[part 1 of 2: package /MICROSAR/Dem_swc/ComponentTypes]
AUTOSAR XML (schema 4-2-2)
package /MICROSAR/Dem_swc/ComponentTypes
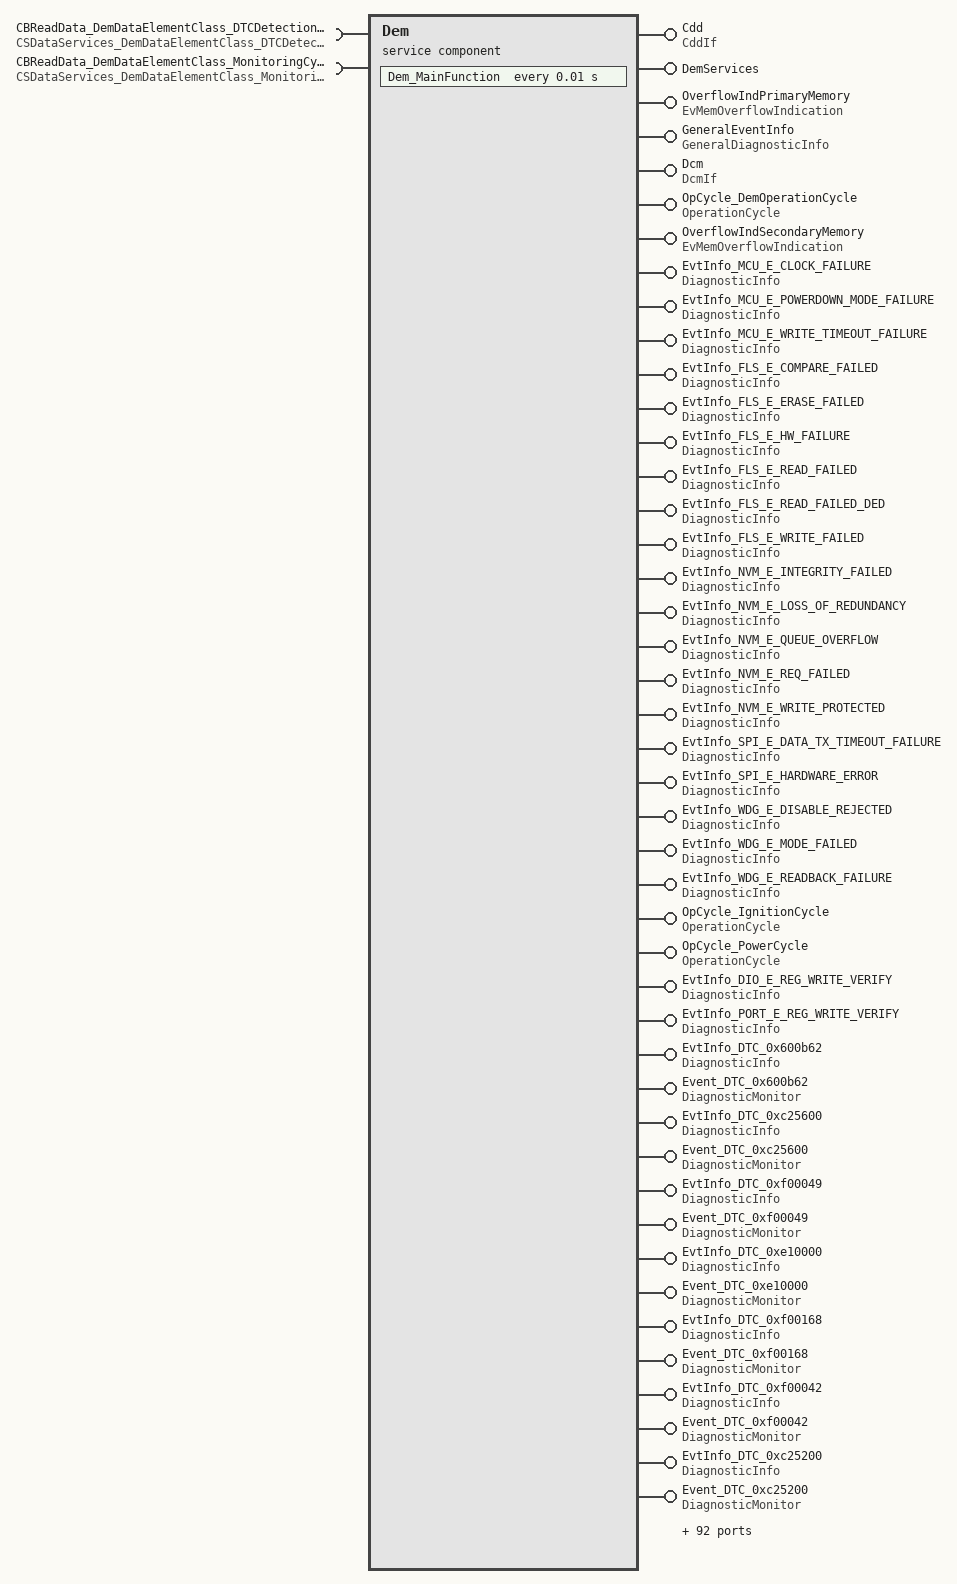
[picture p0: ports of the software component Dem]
  service sw component type Dem: category=SERVICE_COMPONENT
    136 x provide port:
      Cdd: provided-interface=CddIf
      DemServices: provided-interface=DemServices
      OverflowIndPrimaryMemory: provided-interface=EvMemOverflowIndication
      GeneralEventInfo: provided-interface=GeneralDiagnosticInfo
      Dcm: provided-interface=DcmIf
      OpCycle_DemOperationCycle: provided-interface=OperationCycle
      OverflowIndSecondaryMemory: provided-interface=EvMemOverflowIndication
      EvtInfo_MCU_E_CLOCK_FAILURE: provided-interface=DiagnosticInfo
      EvtInfo_MCU_E_POWERDOWN_MODE_FAILURE: provided-interface=DiagnosticInfo
      EvtInfo_MCU_E_WRITE_TIMEOUT_FAILURE: provided-interface=DiagnosticInfo
      EvtInfo_FLS_E_COMPARE_FAILED: provided-interface=DiagnosticInfo
      EvtInfo_FLS_E_ERASE_FAILED: provided-interface=DiagnosticInfo
      EvtInfo_FLS_E_HW_FAILURE: provided-interface=DiagnosticInfo
      EvtInfo_FLS_E_READ_FAILED: provided-interface=DiagnosticInfo
      EvtInfo_FLS_E_READ_FAILED_DED: provided-interface=DiagnosticInfo
      EvtInfo_FLS_E_WRITE_FAILED: provided-interface=DiagnosticInfo
      EvtInfo_NVM_E_INTEGRITY_FAILED: provided-interface=DiagnosticInfo
      EvtInfo_NVM_E_LOSS_OF_REDUNDANCY: provided-interface=DiagnosticInfo
      EvtInfo_NVM_E_QUEUE_OVERFLOW: provided-interface=DiagnosticInfo
      EvtInfo_NVM_E_REQ_FAILED: provided-interface=DiagnosticInfo
      EvtInfo_NVM_E_WRITE_PROTECTED: provided-interface=DiagnosticInfo
      EvtInfo_SPI_E_DATA_TX_TIMEOUT_FAILURE: provided-interface=DiagnosticInfo
      EvtInfo_SPI_E_HARDWARE_ERROR: provided-interface=DiagnosticInfo
      EvtInfo_WDG_E_DISABLE_REJECTED: provided-interface=DiagnosticInfo
      EvtInfo_WDG_E_MODE_FAILED: provided-interface=DiagnosticInfo
      EvtInfo_WDG_E_READBACK_FAILURE: provided-interface=DiagnosticInfo
      OpCycle_IgnitionCycle: provided-interface=OperationCycle
      OpCycle_PowerCycle: provided-interface=OperationCycle
      EvtInfo_DIO_E_REG_WRITE_VERIFY: provided-interface=DiagnosticInfo
      EvtInfo_PORT_E_REG_WRITE_VERIFY: provided-interface=DiagnosticInfo
      EvtInfo_DTC_0x600b62: provided-interface=DiagnosticInfo
      Event_DTC_0x600b62: provided-interface=DiagnosticMonitor
      EvtInfo_DTC_0xc25600: provided-interface=DiagnosticInfo
      Event_DTC_0xc25600: provided-interface=DiagnosticMonitor
      EvtInfo_DTC_0xf00049: provided-interface=DiagnosticInfo
      Event_DTC_0xf00049: provided-interface=DiagnosticMonitor
      EvtInfo_DTC_0xe10000: provided-interface=DiagnosticInfo
      Event_DTC_0xe10000: provided-interface=DiagnosticMonitor
      EvtInfo_DTC_0xf00168: provided-interface=DiagnosticInfo
      Event_DTC_0xf00168: provided-interface=DiagnosticMonitor
      EvtInfo_DTC_0xf00042: provided-interface=DiagnosticInfo
      Event_DTC_0xf00042: provided-interface=DiagnosticMonitor
      EvtInfo_DTC_0xc25200: provided-interface=DiagnosticInfo
      Event_DTC_0xc25200: provided-interface=DiagnosticMonitor
      EvtInfo_DTC_0xe01492: provided-interface=DiagnosticInfo
      Event_DTC_0xe01492: provided-interface=DiagnosticMonitor
      EvtInfo_DTC_0xc41522: provided-interface=DiagnosticInfo
      Event_DTC_0xc41522: provided-interface=DiagnosticMonitor
      EvtInfo_DTC_0xc55700: provided-interface=DiagnosticInfo
      Event_DTC_0xc55700: provided-interface=DiagnosticMonitor
      EvtInfo_DTC_0xc55300: provided-interface=DiagnosticInfo
      Event_DTC_0xc55300: provided-interface=DiagnosticMonitor
      EvtInfo_DTC_0x5b0062: provided-interface=DiagnosticInfo
      Event_DTC_0x5b0062: provided-interface=DiagnosticMonitor
      EvtInfo_DTC_0x511056: provided-interface=DiagnosticInfo
      Event_DTC_0x511056: provided-interface=DiagnosticMonitor
      EvtInfo_DTC_0xc10000: provided-interface=DiagnosticInfo
      Event_DTC_0xc10000: provided-interface=DiagnosticMonitor
      EvtInfo_DTC_0xe01481: provided-interface=DiagnosticInfo
      Event_DTC_0xe01481: provided-interface=DiagnosticMonitor
      EvtInfo_DTC_0xc14600: provided-interface=DiagnosticInfo
      Event_DTC_0xc14600: provided-interface=DiagnosticMonitor
      EvtInfo_DTC_0xe01647: provided-interface=DiagnosticInfo
      Event_DTC_0xe01647: provided-interface=DiagnosticMonitor
      EvtInfo_DTC_0xe01648: provided-interface=DiagnosticInfo
      Event_DTC_0xe01648: provided-interface=DiagnosticMonitor
      EvtInfo_DTC_0xc40100: provided-interface=DiagnosticInfo
      Event_DTC_0xc40100: provided-interface=DiagnosticMonitor
      EvtInfo_DTC_0xc53b00: provided-interface=DiagnosticInfo
      Event_DTC_0xc53b00: provided-interface=DiagnosticMonitor
      EvtInfo_DTC_0xf00061: provided-interface=DiagnosticInfo
      Event_DTC_0xf00061: provided-interface=DiagnosticMonitor
      EvtInfo_DTC_0x600d49: provided-interface=DiagnosticInfo
      Event_DTC_0x600d49: provided-interface=DiagnosticMonitor
      EvtInfo_DTC_0xc55400: provided-interface=DiagnosticInfo
      Event_DTC_0xc55400: provided-interface=DiagnosticMonitor
      EvtInfo_DTC_0xe01478: provided-interface=DiagnosticInfo
      Event_DTC_0xe01478: provided-interface=DiagnosticMonitor
      EvtInfo_DTC_0x502d00: provided-interface=DiagnosticInfo
      Event_DTC_0x502d00: provided-interface=DiagnosticMonitor
      EvtInfo_DTC_0xc12200: provided-interface=DiagnosticInfo
      Event_DTC_0xc12200: provided-interface=DiagnosticMonitor
      EvtInfo_DTC_0xc12600: provided-interface=DiagnosticInfo
      Event_DTC_0xc12600: provided-interface=DiagnosticMonitor
      EvtInfo_DTC_0xf00368: provided-interface=DiagnosticInfo
      Event_DTC_0xf00368: provided-interface=DiagnosticMonitor
      EvtInfo_DTC_0x600d62: provided-interface=DiagnosticInfo
      Event_DTC_0x600d62: provided-interface=DiagnosticMonitor
      EvtInfo_DTC_0xc42300: provided-interface=DiagnosticInfo
      Event_DTC_0xc42300: provided-interface=DiagnosticMonitor
      EvtInfo_DTC_0xc53c00: provided-interface=DiagnosticInfo
      Event_DTC_0xc53c00: provided-interface=DiagnosticMonitor
      EvtInfo_DTC_0xe30055: provided-interface=DiagnosticInfo
      Event_DTC_0xe30055: provided-interface=DiagnosticMonitor
      EvtInfo_DTC_0x600c49: provided-interface=DiagnosticInfo
      Event_DTC_0x600c49: provided-interface=DiagnosticMonitor
      EvtInfo_DTC_0xc23b00: provided-interface=DiagnosticInfo
      Event_DTC_0xc23b00: provided-interface=DiagnosticMonitor
      EvtInfo_DTC_0xc41600: provided-interface=DiagnosticInfo
      Event_DTC_0xc41600: provided-interface=DiagnosticMonitor
      EvtInfo_DTC_0x9d234b: provided-interface=DiagnosticInfo
      Event_DTC_0x9d234b: provided-interface=DiagnosticMonitor
      EvtInfo_DTC_0xc10200: provided-interface=DiagnosticInfo
      Event_DTC_0xc10200: provided-interface=DiagnosticMonitor
      EvtInfo_DTC_0xc12100: provided-interface=DiagnosticInfo
      Event_DTC_0xc12100: provided-interface=DiagnosticMonitor
      EvtInfo_DTC_0xc42800: provided-interface=DiagnosticInfo
      Event_DTC_0xc42800: provided-interface=DiagnosticMonitor
      EvtInfo_DTC_0xc14000: provided-interface=DiagnosticInfo
      Event_DTC_0xc14000: provided-interface=DiagnosticMonitor
      EvtInfo_DTC_0xc45a00: provided-interface=DiagnosticInfo
      Event_DTC_0xc45a00: provided-interface=DiagnosticMonitor
      EvtInfo_DTC_0xc25300: provided-interface=DiagnosticInfo
      Event_DTC_0xc25300: provided-interface=DiagnosticMonitor
      EvtInfo_DTC_0x600c62: provided-interface=DiagnosticInfo
      Event_DTC_0x600c62: provided-interface=DiagnosticMonitor
      EvtInfo_DTC_0xc42200: provided-interface=DiagnosticInfo
      Event_DTC_0xc42200: provided-interface=DiagnosticMonitor
      EvtInfo_DTC_0xc40300: provided-interface=DiagnosticInfo
      Event_DTC_0xc40300: provided-interface=DiagnosticMonitor
      EvtInfo_DTC_0x600b49: provided-interface=DiagnosticInfo
      Event_DTC_0x600b49: provided-interface=DiagnosticMonitor
      EvtInfo_DTC_0xc15900: provided-interface=DiagnosticInfo
      Event_DTC_0xc15900: provided-interface=DiagnosticMonitor
      EvtInfo_DTC_0xc23a00: provided-interface=DiagnosticInfo
      Event_DTC_0xc23a00: provided-interface=DiagnosticMonitor
      EvtInfo_DTC_0xc15500: provided-interface=DiagnosticInfo
      Event_DTC_0xc15500: provided-interface=DiagnosticMonitor
      EvtInfo_DTC_0xc41500: provided-interface=DiagnosticInfo
      Event_DTC_0xc41500: provided-interface=DiagnosticMonitor
      EvtInfo_DTC_0x5b0049: provided-interface=DiagnosticInfo
      Event_DTC_0x5b0049: provided-interface=DiagnosticMonitor
      EvtInfo_DTC_0xf00317: provided-interface=DiagnosticInfo
      Event_DTC_0xf00317: provided-interface=DiagnosticMonitor
      EvtInfo_DTC_0xf00316: provided-interface=DiagnosticInfo
      Event_DTC_0xf00316: provided-interface=DiagnosticMonitor
    require port CBReadData_DemDataElementClass_DTCDetectionCounter: required-interface=CSDataServices_DemDataElementClass_DTCDetectionCounter
    require port CBReadData_DemDataElementClass_MonitoringCycleCounter2: required-interface=CSDataServices_DemDataElementClass_MonitoringCycleCounter2
    behavior DemInternalBehavior: handle-termination-and-restart=NO-SUPPORT, included-data-type-set=data-type=[Dem_EventIdType, Dem_RatioIdType, Dem_EventStatusType, Dem_EventStatusExtendedType, Dem_UdsStatusByteType, Dem_DTCFormatType, Dem_InitMonitorReasonType, Dem_OperationCycleStateType, Dem_DTCStatusMaskType, Dem_IndicatorStatusType, Dem_MaxDataValueType, Dem_DTCKindType, Dem_DTCGroupType, Dem_IumprDenomCondIdType, Dem_IumprDenomCondStatusType, Dem_DebounceResetStatusType, Dem_DebouncingStateType]
      timing event Timer_Dem_MainFunction: start-on-event=Dem_MainFunction, period=0.01
      1220 x operation invoked event:
        OpEventClearDTC_ClearDTC_Cdd: start-on-event=ClearDTC, operation=Cdd.ClearDTC
        OpEventPostRunRequested_GetPostRunRequested_DemServices: start-on-event=PostRunRequested, operation=DemServices.GetPostRunRequested
        OpEventGetDTCStatusAvailabilityMask_GetDTCStatusAvailabilityMask_DemServices: start-on-event=GetDTCStatusAvailabilityMask, operation=DemServices.GetDTCStatusAvailabilityMask
        OpEventGetEventMemoryOverflow_GetEventMemoryOverflow_OverflowIndPrimaryMemory: start-on-event=GetEventMemoryOverflow, operation=OverflowIndPrimaryMemory.GetEventMemoryOverflow
        OpEventGetNumberOfEventMemoryEntries_GetNumberOfEventMemoryEntries_OverflowIndPrimaryMemory: start-on-event=GetNumberOfEventMemoryEntries, operation=OverflowIndPrimaryMemory.GetNumberOfEventMemoryEntries
        OpEventGetEventStatus_GetEventStatus_GeneralEventInfo: start-on-event=GetEventStatus, operation=GeneralEventInfo.GetEventStatus
        OpEventGetEventFailed_GetEventFailed_GeneralEventInfo: start-on-event=GetEventFailed, operation=GeneralEventInfo.GetEventFailed
        OpEventGetEventTested_GetEventTested_GeneralEventInfo: start-on-event=GetEventTested, operation=GeneralEventInfo.GetEventTested
        OpEventGetDTCOfEvent_GetDTCOfEvent_GeneralEventInfo: start-on-event=GetDTCOfEvent, operation=GeneralEventInfo.GetDTCOfEvent
        OpEventGetFaultDetectionCounter_GetFaultDetectionCounter_GeneralEventInfo: start-on-event=GetFaultDetectionCounter, operation=GeneralEventInfo.GetFaultDetectionCounter
        OpEventGetEventFreezeFrameData_GetEventFreezeFrameData_GeneralEventInfo: start-on-event=GetEventFreezeFrameData, operation=GeneralEventInfo.GetEventFreezeFrameData
        OpEventGetEventExtendedDataRecord_GetEventExtendedDataRecord_GeneralEventInfo: start-on-event=GetEventExtendedDataRecord, operation=GeneralEventInfo.GetEventExtendedDataRecord
        OpEventGetEventEnableCondition_GetEventEnableCondition_GeneralEventInfo: start-on-event=GetEventEnableCondition, operation=GeneralEventInfo.GetEventEnableCondition
        OpEventGetDebouncingOfEvent_GetDebouncingOfEvent_GeneralEventInfo: start-on-event=GetDebouncingOfEvent, operation=GeneralEventInfo.GetDebouncingOfEvent
        OpEventDcmClearDTC_DcmClearDTC_Dcm: start-on-event=DcmClearDTC, operation=Dcm.DcmClearDTC
        OpEventDcmGetNextFilteredDTCAndFDC_DcmGetNextFilteredDTCAndFDC_Dcm: start-on-event=DcmGetNextFilteredDTCAndFDC, operation=Dcm.DcmGetNextFilteredDTCAndFDC
        OpEventDcmEnableDTCSetting_DcmEnableDTCSetting_Dcm: start-on-event=DcmEnableDTCSetting, operation=Dcm.DcmEnableDTCSetting
        OpEventDcmGetFreezeFrameDataByDTC_DcmGetFreezeFrameDataByDTC_Dcm: start-on-event=DcmGetFreezeFrameDataByDTC, operation=Dcm.DcmGetFreezeFrameDataByDTC
        OpEventDcmGetExtendedDataRecordByDTC_DcmGetExtendedDataRecordByDTC_Dcm: start-on-event=DcmGetExtendedDataRecordByDTC, operation=Dcm.DcmGetExtendedDataRecordByDTC
        OpEventSetOperationCycleState_SetOperationCycleState_OpCycle_DemOperationCycle: start-on-event=SetOperationCycleState, operation=OpCycle_DemOperationCycle.SetOperationCycleState
        OpEventGetEventMemoryOverflow_GetEventMemoryOverflow_OverflowIndSecondaryMemory: start-on-event=GetEventMemoryOverflow, operation=OverflowIndSecondaryMemory.GetEventMemoryOverflow
        OpEventGetNumberOfEventMemoryEntries_GetNumberOfEventMemoryEntries_OverflowIndSecondaryMemory: start-on-event=GetNumberOfEventMemoryEntries, operation=OverflowIndSecondaryMemory.GetNumberOfEventMemoryEntries
        OpEventGetEventStatus_GetEventStatus_EvtInfo_MCU_E_CLOCK_FAILURE: start-on-event=GetEventStatus, operation=EvtInfo_MCU_E_CLOCK_FAILURE.GetEventStatus
        OpEventGetEventStatus_GetEventStatus_EvtInfo_MCU_E_POWERDOWN_MODE_FAILURE: start-on-event=GetEventStatus, operation=EvtInfo_MCU_E_POWERDOWN_MODE_FAILURE.GetEventStatus
        OpEventGetEventStatus_GetEventStatus_EvtInfo_MCU_E_WRITE_TIMEOUT_FAILURE: start-on-event=GetEventStatus, operation=EvtInfo_MCU_E_WRITE_TIMEOUT_FAILURE.GetEventStatus
        OpEventGetEventStatus_GetEventStatus_EvtInfo_FLS_E_COMPARE_FAILED: start-on-event=GetEventStatus, operation=EvtInfo_FLS_E_COMPARE_FAILED.GetEventStatus
        OpEventGetEventStatus_GetEventStatus_EvtInfo_FLS_E_ERASE_FAILED: start-on-event=GetEventStatus, operation=EvtInfo_FLS_E_ERASE_FAILED.GetEventStatus
        OpEventGetEventStatus_GetEventStatus_EvtInfo_FLS_E_HW_FAILURE: start-on-event=GetEventStatus, operation=EvtInfo_FLS_E_HW_FAILURE.GetEventStatus
        OpEventGetEventStatus_GetEventStatus_EvtInfo_FLS_E_READ_FAILED: start-on-event=GetEventStatus, operation=EvtInfo_FLS_E_READ_FAILED.GetEventStatus
        OpEventGetEventStatus_GetEventStatus_EvtInfo_FLS_E_READ_FAILED_DED: start-on-event=GetEventStatus, operation=EvtInfo_FLS_E_READ_FAILED_DED.GetEventStatus
        OpEventGetEventStatus_GetEventStatus_EvtInfo_FLS_E_WRITE_FAILED: start-on-event=GetEventStatus, operation=EvtInfo_FLS_E_WRITE_FAILED.GetEventStatus
        OpEventGetEventStatus_GetEventStatus_EvtInfo_NVM_E_INTEGRITY_FAILED: start-on-event=GetEventStatus, operation=EvtInfo_NVM_E_INTEGRITY_FAILED.GetEventStatus
        OpEventGetEventStatus_GetEventStatus_EvtInfo_NVM_E_LOSS_OF_REDUNDANCY: start-on-event=GetEventStatus, operation=EvtInfo_NVM_E_LOSS_OF_REDUNDANCY.GetEventStatus
        OpEventGetEventStatus_GetEventStatus_EvtInfo_NVM_E_QUEUE_OVERFLOW: start-on-event=GetEventStatus, operation=EvtInfo_NVM_E_QUEUE_OVERFLOW.GetEventStatus
        OpEventGetEventStatus_GetEventStatus_EvtInfo_NVM_E_REQ_FAILED: start-on-event=GetEventStatus, operation=EvtInfo_NVM_E_REQ_FAILED.GetEventStatus
        OpEventGetEventStatus_GetEventStatus_EvtInfo_NVM_E_WRITE_PROTECTED: start-on-event=GetEventStatus, operation=EvtInfo_NVM_E_WRITE_PROTECTED.GetEventStatus
        OpEventGetEventStatus_GetEventStatus_EvtInfo_SPI_E_DATA_TX_TIMEOUT_FAILURE: start-on-event=GetEventStatus, operation=EvtInfo_SPI_E_DATA_TX_TIMEOUT_FAILURE.GetEventStatus
        OpEventGetEventStatus_GetEventStatus_EvtInfo_SPI_E_HARDWARE_ERROR: start-on-event=GetEventStatus, operation=EvtInfo_SPI_E_HARDWARE_ERROR.GetEventStatus
        OpEventGetEventStatus_GetEventStatus_EvtInfo_WDG_E_DISABLE_REJECTED: start-on-event=GetEventStatus, operation=EvtInfo_WDG_E_DISABLE_REJECTED.GetEventStatus
        OpEventGetEventStatus_GetEventStatus_EvtInfo_WDG_E_MODE_FAILED: start-on-event=GetEventStatus, operation=EvtInfo_WDG_E_MODE_FAILED.GetEventStatus
        OpEventGetEventStatus_GetEventStatus_EvtInfo_WDG_E_READBACK_FAILURE: start-on-event=GetEventStatus, operation=EvtInfo_WDG_E_READBACK_FAILURE.GetEventStatus
        OpEventGetEventFailed_GetEventFailed_EvtInfo_MCU_E_CLOCK_FAILURE: start-on-event=GetEventFailed, operation=EvtInfo_MCU_E_CLOCK_FAILURE.GetEventFailed
        OpEventGetEventFailed_GetEventFailed_EvtInfo_MCU_E_POWERDOWN_MODE_FAILURE: start-on-event=GetEventFailed, operation=EvtInfo_MCU_E_POWERDOWN_MODE_FAILURE.GetEventFailed
        OpEventGetEventFailed_GetEventFailed_EvtInfo_MCU_E_WRITE_TIMEOUT_FAILURE: start-on-event=GetEventFailed, operation=EvtInfo_MCU_E_WRITE_TIMEOUT_FAILURE.GetEventFailed
        OpEventGetEventFailed_GetEventFailed_EvtInfo_FLS_E_COMPARE_FAILED: start-on-event=GetEventFailed, operation=EvtInfo_FLS_E_COMPARE_FAILED.GetEventFailed
        OpEventGetEventFailed_GetEventFailed_EvtInfo_FLS_E_ERASE_FAILED: start-on-event=GetEventFailed, operation=EvtInfo_FLS_E_ERASE_FAILED.GetEventFailed
        OpEventGetEventFailed_GetEventFailed_EvtInfo_FLS_E_HW_FAILURE: start-on-event=GetEventFailed, operation=EvtInfo_FLS_E_HW_FAILURE.GetEventFailed
        OpEventGetEventFailed_GetEventFailed_EvtInfo_FLS_E_READ_FAILED: start-on-event=GetEventFailed, operation=EvtInfo_FLS_E_READ_FAILED.GetEventFailed
        OpEventGetEventFailed_GetEventFailed_EvtInfo_FLS_E_READ_FAILED_DED: start-on-event=GetEventFailed, operation=EvtInfo_FLS_E_READ_FAILED_DED.GetEventFailed
        OpEventGetEventFailed_GetEventFailed_EvtInfo_FLS_E_WRITE_FAILED: start-on-event=GetEventFailed, operation=EvtInfo_FLS_E_WRITE_FAILED.GetEventFailed
        OpEventGetEventFailed_GetEventFailed_EvtInfo_NVM_E_INTEGRITY_FAILED: start-on-event=GetEventFailed, operation=EvtInfo_NVM_E_INTEGRITY_FAILED.GetEventFailed
        OpEventGetEventFailed_GetEventFailed_EvtInfo_NVM_E_LOSS_OF_REDUNDANCY: start-on-event=GetEventFailed, operation=EvtInfo_NVM_E_LOSS_OF_REDUNDANCY.GetEventFailed
        OpEventGetEventFailed_GetEventFailed_EvtInfo_NVM_E_QUEUE_OVERFLOW: start-on-event=GetEventFailed, operation=EvtInfo_NVM_E_QUEUE_OVERFLOW.GetEventFailed
        OpEventGetEventFailed_GetEventFailed_EvtInfo_NVM_E_REQ_FAILED: start-on-event=GetEventFailed, operation=EvtInfo_NVM_E_REQ_FAILED.GetEventFailed
        OpEventGetEventFailed_GetEventFailed_EvtInfo_NVM_E_WRITE_PROTECTED: start-on-event=GetEventFailed, operation=EvtInfo_NVM_E_WRITE_PROTECTED.GetEventFailed
        OpEventGetEventFailed_GetEventFailed_EvtInfo_SPI_E_DATA_TX_TIMEOUT_FAILURE: start-on-event=GetEventFailed, operation=EvtInfo_SPI_E_DATA_TX_TIMEOUT_FAILURE.GetEventFailed
        OpEventGetEventFailed_GetEventFailed_EvtInfo_SPI_E_HARDWARE_ERROR: start-on-event=GetEventFailed, operation=EvtInfo_SPI_E_HARDWARE_ERROR.GetEventFailed
        OpEventGetEventFailed_GetEventFailed_EvtInfo_WDG_E_DISABLE_REJECTED: start-on-event=GetEventFailed, operation=EvtInfo_WDG_E_DISABLE_REJECTED.GetEventFailed
        OpEventGetEventFailed_GetEventFailed_EvtInfo_WDG_E_MODE_FAILED: start-on-event=GetEventFailed, operation=EvtInfo_WDG_E_MODE_FAILED.GetEventFailed
        OpEventGetEventFailed_GetEventFailed_EvtInfo_WDG_E_READBACK_FAILURE: start-on-event=GetEventFailed, operation=EvtInfo_WDG_E_READBACK_FAILURE.GetEventFailed
        OpEventGetEventTested_GetEventTested_EvtInfo_MCU_E_CLOCK_FAILURE: start-on-event=GetEventTested, operation=EvtInfo_MCU_E_CLOCK_FAILURE.GetEventTested
        OpEventGetEventTested_GetEventTested_EvtInfo_MCU_E_POWERDOWN_MODE_FAILURE: start-on-event=GetEventTested, operation=EvtInfo_MCU_E_POWERDOWN_MODE_FAILURE.GetEventTested
        OpEventGetEventTested_GetEventTested_EvtInfo_MCU_E_WRITE_TIMEOUT_FAILURE: start-on-event=GetEventTested, operation=EvtInfo_MCU_E_WRITE_TIMEOUT_FAILURE.GetEventTested
        OpEventGetEventTested_GetEventTested_EvtInfo_FLS_E_COMPARE_FAILED: start-on-event=GetEventTested, operation=EvtInfo_FLS_E_COMPARE_FAILED.GetEventTested
        OpEventGetEventTested_GetEventTested_EvtInfo_FLS_E_ERASE_FAILED: start-on-event=GetEventTested, operation=EvtInfo_FLS_E_ERASE_FAILED.GetEventTested
        OpEventGetEventTested_GetEventTested_EvtInfo_FLS_E_HW_FAILURE: start-on-event=GetEventTested, operation=EvtInfo_FLS_E_HW_FAILURE.GetEventTested
        OpEventGetEventTested_GetEventTested_EvtInfo_FLS_E_READ_FAILED: start-on-event=GetEventTested, operation=EvtInfo_FLS_E_READ_FAILED.GetEventTested
        OpEventGetEventTested_GetEventTested_EvtInfo_FLS_E_READ_FAILED_DED: start-on-event=GetEventTested, operation=EvtInfo_FLS_E_READ_FAILED_DED.GetEventTested
        OpEventGetEventTested_GetEventTested_EvtInfo_FLS_E_WRITE_FAILED: start-on-event=GetEventTested, operation=EvtInfo_FLS_E_WRITE_FAILED.GetEventTested
        OpEventGetEventTested_GetEventTested_EvtInfo_NVM_E_INTEGRITY_FAILED: start-on-event=GetEventTested, operation=EvtInfo_NVM_E_INTEGRITY_FAILED.GetEventTested
        OpEventGetEventTested_GetEventTested_EvtInfo_NVM_E_LOSS_OF_REDUNDANCY: start-on-event=GetEventTested, operation=EvtInfo_NVM_E_LOSS_OF_REDUNDANCY.GetEventTested
        OpEventGetEventTested_GetEventTested_EvtInfo_NVM_E_QUEUE_OVERFLOW: start-on-event=GetEventTested, operation=EvtInfo_NVM_E_QUEUE_OVERFLOW.GetEventTested
        OpEventGetEventTested_GetEventTested_EvtInfo_NVM_E_REQ_FAILED: start-on-event=GetEventTested, operation=EvtInfo_NVM_E_REQ_FAILED.GetEventTested
        OpEventGetEventTested_GetEventTested_EvtInfo_NVM_E_WRITE_PROTECTED: start-on-event=GetEventTested, operation=EvtInfo_NVM_E_WRITE_PROTECTED.GetEventTested
        OpEventGetEventTested_GetEventTested_EvtInfo_SPI_E_DATA_TX_TIMEOUT_FAILURE: start-on-event=GetEventTested, operation=EvtInfo_SPI_E_DATA_TX_TIMEOUT_FAILURE.GetEventTested
        OpEventGetEventTested_GetEventTested_EvtInfo_SPI_E_HARDWARE_ERROR: start-on-event=GetEventTested, operation=EvtInfo_SPI_E_HARDWARE_ERROR.GetEventTested
        OpEventGetEventTested_GetEventTested_EvtInfo_WDG_E_DISABLE_REJECTED: start-on-event=GetEventTested, operation=EvtInfo_WDG_E_DISABLE_REJECTED.GetEventTested
        OpEventGetEventTested_GetEventTested_EvtInfo_WDG_E_MODE_FAILED: start-on-event=GetEventTested, operation=EvtInfo_WDG_E_MODE_FAILED.GetEventTested
        OpEventGetEventTested_GetEventTested_EvtInfo_WDG_E_READBACK_FAILURE: start-on-event=GetEventTested, operation=EvtInfo_WDG_E_READBACK_FAILURE.GetEventTested
        OpEventGetDTCOfEvent_GetDTCOfEvent_EvtInfo_MCU_E_CLOCK_FAILURE: start-on-event=GetDTCOfEvent, operation=EvtInfo_MCU_E_CLOCK_FAILURE.GetDTCOfEvent
        OpEventGetDTCOfEvent_GetDTCOfEvent_EvtInfo_MCU_E_POWERDOWN_MODE_FAILURE: start-on-event=GetDTCOfEvent, operation=EvtInfo_MCU_E_POWERDOWN_MODE_FAILURE.GetDTCOfEvent
        OpEventGetDTCOfEvent_GetDTCOfEvent_EvtInfo_MCU_E_WRITE_TIMEOUT_FAILURE: start-on-event=GetDTCOfEvent, operation=EvtInfo_MCU_E_WRITE_TIMEOUT_FAILURE.GetDTCOfEvent
        OpEventGetDTCOfEvent_GetDTCOfEvent_EvtInfo_FLS_E_COMPARE_FAILED: start-on-event=GetDTCOfEvent, operation=EvtInfo_FLS_E_COMPARE_FAILED.GetDTCOfEvent
        OpEventGetDTCOfEvent_GetDTCOfEvent_EvtInfo_FLS_E_ERASE_FAILED: start-on-event=GetDTCOfEvent, operation=EvtInfo_FLS_E_ERASE_FAILED.GetDTCOfEvent
        OpEventGetDTCOfEvent_GetDTCOfEvent_EvtInfo_FLS_E_HW_FAILURE: start-on-event=GetDTCOfEvent, operation=EvtInfo_FLS_E_HW_FAILURE.GetDTCOfEvent
        OpEventGetDTCOfEvent_GetDTCOfEvent_EvtInfo_FLS_E_READ_FAILED: start-on-event=GetDTCOfEvent, operation=EvtInfo_FLS_E_READ_FAILED.GetDTCOfEvent
        OpEventGetDTCOfEvent_GetDTCOfEvent_EvtInfo_FLS_E_READ_FAILED_DED: start-on-event=GetDTCOfEvent, operation=EvtInfo_FLS_E_READ_FAILED_DED.GetDTCOfEvent
        OpEventGetDTCOfEvent_GetDTCOfEvent_EvtInfo_FLS_E_WRITE_FAILED: start-on-event=GetDTCOfEvent, operation=EvtInfo_FLS_E_WRITE_FAILED.GetDTCOfEvent
        OpEventGetDTCOfEvent_GetDTCOfEvent_EvtInfo_NVM_E_INTEGRITY_FAILED: start-on-event=GetDTCOfEvent, operation=EvtInfo_NVM_E_INTEGRITY_FAILED.GetDTCOfEvent
        OpEventGetDTCOfEvent_GetDTCOfEvent_EvtInfo_NVM_E_LOSS_OF_REDUNDANCY: start-on-event=GetDTCOfEvent, operation=EvtInfo_NVM_E_LOSS_OF_REDUNDANCY.GetDTCOfEvent
        OpEventGetDTCOfEvent_GetDTCOfEvent_EvtInfo_NVM_E_QUEUE_OVERFLOW: start-on-event=GetDTCOfEvent, operation=EvtInfo_NVM_E_QUEUE_OVERFLOW.GetDTCOfEvent
        OpEventGetDTCOfEvent_GetDTCOfEvent_EvtInfo_NVM_E_REQ_FAILED: start-on-event=GetDTCOfEvent, operation=EvtInfo_NVM_E_REQ_FAILED.GetDTCOfEvent
        OpEventGetDTCOfEvent_GetDTCOfEvent_EvtInfo_NVM_E_WRITE_PROTECTED: start-on-event=GetDTCOfEvent, operation=EvtInfo_NVM_E_WRITE_PROTECTED.GetDTCOfEvent
        OpEventGetDTCOfEvent_GetDTCOfEvent_EvtInfo_SPI_E_DATA_TX_TIMEOUT_FAILURE: start-on-event=GetDTCOfEvent, operation=EvtInfo_SPI_E_DATA_TX_TIMEOUT_FAILURE.GetDTCOfEvent
        OpEventGetDTCOfEvent_GetDTCOfEvent_EvtInfo_SPI_E_HARDWARE_ERROR: start-on-event=GetDTCOfEvent, operation=EvtInfo_SPI_E_HARDWARE_ERROR.GetDTCOfEvent
        OpEventGetDTCOfEvent_GetDTCOfEvent_EvtInfo_WDG_E_DISABLE_REJECTED: start-on-event=GetDTCOfEvent, operation=EvtInfo_WDG_E_DISABLE_REJECTED.GetDTCOfEvent
        OpEventGetDTCOfEvent_GetDTCOfEvent_EvtInfo_WDG_E_MODE_FAILED: start-on-event=GetDTCOfEvent, operation=EvtInfo_WDG_E_MODE_FAILED.GetDTCOfEvent
        OpEventGetDTCOfEvent_GetDTCOfEvent_EvtInfo_WDG_E_READBACK_FAILURE: start-on-event=GetDTCOfEvent, operation=EvtInfo_WDG_E_READBACK_FAILURE.GetDTCOfEvent
        OpEventGetFaultDetectionCounter_GetFaultDetectionCounter_EvtInfo_MCU_E_CLOCK_FAILURE: start-on-event=GetFaultDetectionCounter, operation=EvtInfo_MCU_E_CLOCK_FAILURE.GetFaultDetectionCounter
        OpEventGetFaultDetectionCounter_GetFaultDetectionCounter_EvtInfo_MCU_E_POWERDOWN_MODE_FAILURE: start-on-event=GetFaultDetectionCounter, operation=EvtInfo_MCU_E_POWERDOWN_MODE_FAILURE.GetFaultDetectionCounter
        OpEventGetFaultDetectionCounter_GetFaultDetectionCounter_EvtInfo_MCU_E_WRITE_TIMEOUT_FAILURE: start-on-event=GetFaultDetectionCounter, operation=EvtInfo_MCU_E_WRITE_TIMEOUT_FAILURE.GetFaultDetectionCounter
        OpEventGetFaultDetectionCounter_GetFaultDetectionCounter_EvtInfo_FLS_E_COMPARE_FAILED: start-on-event=GetFaultDetectionCounter, operation=EvtInfo_FLS_E_COMPARE_FAILED.GetFaultDetectionCounter
        OpEventGetFaultDetectionCounter_GetFaultDetectionCounter_EvtInfo_FLS_E_ERASE_FAILED: start-on-event=GetFaultDetectionCounter, operation=EvtInfo_FLS_E_ERASE_FAILED.GetFaultDetectionCounter
        OpEventGetFaultDetectionCounter_GetFaultDetectionCounter_EvtInfo_FLS_E_HW_FAILURE: start-on-event=GetFaultDetectionCounter, operation=EvtInfo_FLS_E_HW_FAILURE.GetFaultDetectionCounter
        OpEventGetFaultDetectionCounter_GetFaultDetectionCounter_EvtInfo_FLS_E_READ_FAILED: start-on-event=GetFaultDetectionCounter, operation=EvtInfo_FLS_E_READ_FAILED.GetFaultDetectionCounter
        OpEventGetFaultDetectionCounter_GetFaultDetectionCounter_EvtInfo_FLS_E_READ_FAILED_DED: start-on-event=GetFaultDetectionCounter, operation=EvtInfo_FLS_E_READ_FAILED_DED.GetFaultDetectionCounter
        OpEventGetFaultDetectionCounter_GetFaultDetectionCounter_EvtInfo_FLS_E_WRITE_FAILED: start-on-event=GetFaultDetectionCounter, operation=EvtInfo_FLS_E_WRITE_FAILED.GetFaultDetectionCounter
        OpEventGetFaultDetectionCounter_GetFaultDetectionCounter_EvtInfo_NVM_E_INTEGRITY_FAILED: start-on-event=GetFaultDetectionCounter, operation=EvtInfo_NVM_E_INTEGRITY_FAILED.GetFaultDetectionCounter
        OpEventGetFaultDetectionCounter_GetFaultDetectionCounter_EvtInfo_NVM_E_LOSS_OF_REDUNDANCY: start-on-event=GetFaultDetectionCounter, operation=EvtInfo_NVM_E_LOSS_OF_REDUNDANCY.GetFaultDetectionCounter
        OpEventGetFaultDetectionCounter_GetFaultDetectionCounter_EvtInfo_NVM_E_QUEUE_OVERFLOW: start-on-event=GetFaultDetectionCounter, operation=EvtInfo_NVM_E_QUEUE_OVERFLOW.GetFaultDetectionCounter
        OpEventGetFaultDetectionCounter_GetFaultDetectionCounter_EvtInfo_NVM_E_REQ_FAILED: start-on-event=GetFaultDetectionCounter, operation=EvtInfo_NVM_E_REQ_FAILED.GetFaultDetectionCounter
        OpEventGetFaultDetectionCounter_GetFaultDetectionCounter_EvtInfo_NVM_E_WRITE_PROTECTED: start-on-event=GetFaultDetectionCounter, operation=EvtInfo_NVM_E_WRITE_PROTECTED.GetFaultDetectionCounter
        OpEventGetFaultDetectionCounter_GetFaultDetectionCounter_EvtInfo_SPI_E_DATA_TX_TIMEOUT_FAILURE: start-on-event=GetFaultDetectionCounter, operation=EvtInfo_SPI_E_DATA_TX_TIMEOUT_FAILURE.GetFaultDetectionCounter
        OpEventGetFaultDetectionCounter_GetFaultDetectionCounter_EvtInfo_SPI_E_HARDWARE_ERROR: start-on-event=GetFaultDetectionCounter, operation=EvtInfo_SPI_E_HARDWARE_ERROR.GetFaultDetectionCounter
        OpEventGetFaultDetectionCounter_GetFaultDetectionCounter_EvtInfo_WDG_E_DISABLE_REJECTED: start-on-event=GetFaultDetectionCounter, operation=EvtInfo_WDG_E_DISABLE_REJECTED.GetFaultDetectionCounter
        OpEventGetFaultDetectionCounter_GetFaultDetectionCounter_EvtInfo_WDG_E_MODE_FAILED: start-on-event=GetFaultDetectionCounter, operation=EvtInfo_WDG_E_MODE_FAILED.GetFaultDetectionCounter
        OpEventGetFaultDetectionCounter_GetFaultDetectionCounter_EvtInfo_WDG_E_READBACK_FAILURE: start-on-event=GetFaultDetectionCounter, operation=EvtInfo_WDG_E_READBACK_FAILURE.GetFaultDetectionCounter
        OpEventGetEventFreezeFrameData_GetEventFreezeFrameData_EvtInfo_MCU_E_CLOCK_FAILURE: start-on-event=GetEventFreezeFrameData, operation=EvtInfo_MCU_E_CLOCK_FAILURE.GetEventFreezeFrameData
        OpEventGetEventFreezeFrameData_GetEventFreezeFrameData_EvtInfo_MCU_E_POWERDOWN_MODE_FAILURE: start-on-event=GetEventFreezeFrameData, operation=EvtInfo_MCU_E_POWERDOWN_MODE_FAILURE.GetEventFreezeFrameData
        OpEventGetEventFreezeFrameData_GetEventFreezeFrameData_EvtInfo_MCU_E_WRITE_TIMEOUT_FAILURE: start-on-event=GetEventFreezeFrameData, operation=EvtInfo_MCU_E_WRITE_TIMEOUT_FAILURE.GetEventFreezeFrameData
        OpEventGetEventFreezeFrameData_GetEventFreezeFrameData_EvtInfo_FLS_E_COMPARE_FAILED: start-on-event=GetEventFreezeFrameData, operation=EvtInfo_FLS_E_COMPARE_FAILED.GetEventFreezeFrameData
        OpEventGetEventFreezeFrameData_GetEventFreezeFrameData_EvtInfo_FLS_E_ERASE_FAILED: start-on-event=GetEventFreezeFrameData, operation=EvtInfo_FLS_E_ERASE_FAILED.GetEventFreezeFrameData
        OpEventGetEventFreezeFrameData_GetEventFreezeFrameData_EvtInfo_FLS_E_HW_FAILURE: start-on-event=GetEventFreezeFrameData, operation=EvtInfo_FLS_E_HW_FAILURE.GetEventFreezeFrameData
        OpEventGetEventFreezeFrameData_GetEventFreezeFrameData_EvtInfo_FLS_E_READ_FAILED: start-on-event=GetEventFreezeFrameData, operation=EvtInfo_FLS_E_READ_FAILED.GetEventFreezeFrameData
        OpEventGetEventFreezeFrameData_GetEventFreezeFrameData_EvtInfo_FLS_E_READ_FAILED_DED: start-on-event=GetEventFreezeFrameData, operation=EvtInfo_FLS_E_READ_FAILED_DED.GetEventFreezeFrameData
        OpEventGetEventFreezeFrameData_GetEventFreezeFrameData_EvtInfo_FLS_E_WRITE_FAILED: start-on-event=GetEventFreezeFrameData, operation=EvtInfo_FLS_E_WRITE_FAILED.GetEventFreezeFrameData
        OpEventGetEventFreezeFrameData_GetEventFreezeFrameData_EvtInfo_NVM_E_INTEGRITY_FAILED: start-on-event=GetEventFreezeFrameData, operation=EvtInfo_NVM_E_INTEGRITY_FAILED.GetEventFreezeFrameData
        OpEventGetEventFreezeFrameData_GetEventFreezeFrameData_EvtInfo_NVM_E_LOSS_OF_REDUNDANCY: start-on-event=GetEventFreezeFrameData, operation=EvtInfo_NVM_E_LOSS_OF_REDUNDANCY.GetEventFreezeFrameData
        OpEventGetEventFreezeFrameData_GetEventFreezeFrameData_EvtInfo_NVM_E_QUEUE_OVERFLOW: start-on-event=GetEventFreezeFrameData, operation=EvtInfo_NVM_E_QUEUE_OVERFLOW.GetEventFreezeFrameData
        OpEventGetEventFreezeFrameData_GetEventFreezeFrameData_EvtInfo_NVM_E_REQ_FAILED: start-on-event=GetEventFreezeFrameData, operation=EvtInfo_NVM_E_REQ_FAILED.GetEventFreezeFrameData
        OpEventGetEventFreezeFrameData_GetEventFreezeFrameData_EvtInfo_NVM_E_WRITE_PROTECTED: start-on-event=GetEventFreezeFrameData, operation=EvtInfo_NVM_E_WRITE_PROTECTED.GetEventFreezeFrameData
        OpEventGetEventFreezeFrameData_GetEventFreezeFrameData_EvtInfo_SPI_E_DATA_TX_TIMEOUT_FAILURE: start-on-event=GetEventFreezeFrameData, operation=EvtInfo_SPI_E_DATA_TX_TIMEOUT_FAILURE.GetEventFreezeFrameData
        OpEventGetEventFreezeFrameData_GetEventFreezeFrameData_EvtInfo_SPI_E_HARDWARE_ERROR: start-on-event=GetEventFreezeFrameData, operation=EvtInfo_SPI_E_HARDWARE_ERROR.GetEventFreezeFrameData
        OpEventGetEventFreezeFrameData_GetEventFreezeFrameData_EvtInfo_WDG_E_DISABLE_REJECTED: start-on-event=GetEventFreezeFrameData, operation=EvtInfo_WDG_E_DISABLE_REJECTED.GetEventFreezeFrameData
        OpEventGetEventFreezeFrameData_GetEventFreezeFrameData_EvtInfo_WDG_E_MODE_FAILED: start-on-event=GetEventFreezeFrameData, operation=EvtInfo_WDG_E_MODE_FAILED.GetEventFreezeFrameData
        OpEventGetEventFreezeFrameData_GetEventFreezeFrameData_EvtInfo_WDG_E_READBACK_FAILURE: start-on-event=GetEventFreezeFrameData, operation=EvtInfo_WDG_E_READBACK_FAILURE.GetEventFreezeFrameData
        OpEventGetEventExtendedDataRecord_GetEventExtendedDataRecord_EvtInfo_MCU_E_CLOCK_FAILURE: start-on-event=GetEventExtendedDataRecord, operation=EvtInfo_MCU_E_CLOCK_FAILURE.GetEventExtendedDataRecord
        OpEventGetEventExtendedDataRecord_GetEventExtendedDataRecord_EvtInfo_MCU_E_POWERDOWN_MODE_FAILURE: start-on-event=GetEventExtendedDataRecord, operation=EvtInfo_MCU_E_POWERDOWN_MODE_FAILURE.GetEventExtendedDataRecord
        OpEventGetEventExtendedDataRecord_GetEventExtendedDataRecord_EvtInfo_MCU_E_WRITE_TIMEOUT_FAILURE: start-on-event=GetEventExtendedDataRecord, operation=EvtInfo_MCU_E_WRITE_TIMEOUT_FAILURE.GetEventExtendedDataRecord
        OpEventGetEventExtendedDataRecord_GetEventExtendedDataRecord_EvtInfo_FLS_E_COMPARE_FAILED: start-on-event=GetEventExtendedDataRecord, operation=EvtInfo_FLS_E_COMPARE_FAILED.GetEventExtendedDataRecord
        OpEventGetEventExtendedDataRecord_GetEventExtendedDataRecord_EvtInfo_FLS_E_ERASE_FAILED: start-on-event=GetEventExtendedDataRecord, operation=EvtInfo_FLS_E_ERASE_FAILED.GetEventExtendedDataRecord
        OpEventGetEventExtendedDataRecord_GetEventExtendedDataRecord_EvtInfo_FLS_E_HW_FAILURE: start-on-event=GetEventExtendedDataRecord, operation=EvtInfo_FLS_E_HW_FAILURE.GetEventExtendedDataRecord
        OpEventGetEventExtendedDataRecord_GetEventExtendedDataRecord_EvtInfo_FLS_E_READ_FAILED: start-on-event=GetEventExtendedDataRecord, operation=EvtInfo_FLS_E_READ_FAILED.GetEventExtendedDataRecord
        OpEventGetEventExtendedDataRecord_GetEventExtendedDataRecord_EvtInfo_FLS_E_READ_FAILED_DED: start-on-event=GetEventExtendedDataRecord, operation=EvtInfo_FLS_E_READ_FAILED_DED.GetEventExtendedDataRecord
        OpEventGetEventExtendedDataRecord_GetEventExtendedDataRecord_EvtInfo_FLS_E_WRITE_FAILED: start-on-event=GetEventExtendedDataRecord, operation=EvtInfo_FLS_E_WRITE_FAILED.GetEventExtendedDataRecord
        OpEventGetEventExtendedDataRecord_GetEventExtendedDataRecord_EvtInfo_NVM_E_INTEGRITY_FAILED: start-on-event=GetEventExtendedDataRecord, operation=EvtInfo_NVM_E_INTEGRITY_FAILED.GetEventExtendedDataRecord
        OpEventGetEventExtendedDataRecord_GetEventExtendedDataRecord_EvtInfo_NVM_E_LOSS_OF_REDUNDANCY: start-on-event=GetEventExtendedDataRecord, operation=EvtInfo_NVM_E_LOSS_OF_REDUNDANCY.GetEventExtendedDataRecord
        OpEventGetEventExtendedDataRecord_GetEventExtendedDataRecord_EvtInfo_NVM_E_QUEUE_OVERFLOW: start-on-event=GetEventExtendedDataRecord, operation=EvtInfo_NVM_E_QUEUE_OVERFLOW.GetEventExtendedDataRecord
        OpEventGetEventExtendedDataRecord_GetEventExtendedDataRecord_EvtInfo_NVM_E_REQ_FAILED: start-on-event=GetEventExtendedDataRecord, operation=EvtInfo_NVM_E_REQ_FAILED.GetEventExtendedDataRecord
        OpEventGetEventExtendedDataRecord_GetEventExtendedDataRecord_EvtInfo_NVM_E_WRITE_PROTECTED: start-on-event=GetEventExtendedDataRecord, operation=EvtInfo_NVM_E_WRITE_PROTECTED.GetEventExtendedDataRecord
        OpEventGetEventExtendedDataRecord_GetEventExtendedDataRecord_EvtInfo_SPI_E_DATA_TX_TIMEOUT_FAILURE: start-on-event=GetEventExtendedDataRecord, operation=EvtInfo_SPI_E_DATA_TX_TIMEOUT_FAILURE.GetEventExtendedDataRecord
        OpEventGetEventExtendedDataRecord_GetEventExtendedDataRecord_EvtInfo_SPI_E_HARDWARE_ERROR: start-on-event=GetEventExtendedDataRecord, operation=EvtInfo_SPI_E_HARDWARE_ERROR.GetEventExtendedDataRecord
        OpEventGetEventExtendedDataRecord_GetEventExtendedDataRecord_EvtInfo_WDG_E_DISABLE_REJECTED: start-on-event=GetEventExtendedDataRecord, operation=EvtInfo_WDG_E_DISABLE_REJECTED.GetEventExtendedDataRecord
        OpEventGetEventExtendedDataRecord_GetEventExtendedDataRecord_EvtInfo_WDG_E_MODE_FAILED: start-on-event=GetEventExtendedDataRecord, operation=EvtInfo_WDG_E_MODE_FAILED.GetEventExtendedDataRecord
        OpEventGetEventExtendedDataRecord_GetEventExtendedDataRecord_EvtInfo_WDG_E_READBACK_FAILURE: start-on-event=GetEventExtendedDataRecord, operation=EvtInfo_WDG_E_READBACK_FAILURE.GetEventExtendedDataRecord
        OpEventGetEventEnableCondition_GetEventEnableCondition_EvtInfo_MCU_E_CLOCK_FAILURE: start-on-event=GetEventEnableCondition, operation=EvtInfo_MCU_E_CLOCK_FAILURE.GetEventEnableCondition
        OpEventGetEventEnableCondition_GetEventEnableCondition_EvtInfo_MCU_E_POWERDOWN_MODE_FAILURE: start-on-event=GetEventEnableCondition, operation=EvtInfo_MCU_E_POWERDOWN_MODE_FAILURE.GetEventEnableCondition
        OpEventGetEventEnableCondition_GetEventEnableCondition_EvtInfo_MCU_E_WRITE_TIMEOUT_FAILURE: start-on-event=GetEventEnableCondition, operation=EvtInfo_MCU_E_WRITE_TIMEOUT_FAILURE.GetEventEnableCondition
        OpEventGetEventEnableCondition_GetEventEnableCondition_EvtInfo_FLS_E_COMPARE_FAILED: start-on-event=GetEventEnableCondition, operation=EvtInfo_FLS_E_COMPARE_FAILED.GetEventEnableCondition
        OpEventGetEventEnableCondition_GetEventEnableCondition_EvtInfo_FLS_E_ERASE_FAILED: start-on-event=GetEventEnableCondition, operation=EvtInfo_FLS_E_ERASE_FAILED.GetEventEnableCondition
        OpEventGetEventEnableCondition_GetEventEnableCondition_EvtInfo_FLS_E_HW_FAILURE: start-on-event=GetEventEnableCondition, operation=EvtInfo_FLS_E_HW_FAILURE.GetEventEnableCondition
        OpEventGetEventEnableCondition_GetEventEnableCondition_EvtInfo_FLS_E_READ_FAILED: start-on-event=GetEventEnableCondition, operation=EvtInfo_FLS_E_READ_FAILED.GetEventEnableCondition
        OpEventGetEventEnableCondition_GetEventEnableCondition_EvtInfo_FLS_E_READ_FAILED_DED: start-on-event=GetEventEnableCondition, operation=EvtInfo_FLS_E_READ_FAILED_DED.GetEventEnableCondition
        OpEventGetEventEnableCondition_GetEventEnableCondition_EvtInfo_FLS_E_WRITE_FAILED: start-on-event=GetEventEnableCondition, operation=EvtInfo_FLS_E_WRITE_FAILED.GetEventEnableCondition
        OpEventGetEventEnableCondition_GetEventEnableCondition_EvtInfo_NVM_E_INTEGRITY_FAILED: start-on-event=GetEventEnableCondition, operation=EvtInfo_NVM_E_INTEGRITY_FAILED.GetEventEnableCondition
        OpEventGetEventEnableCondition_GetEventEnableCondition_EvtInfo_NVM_E_LOSS_OF_REDUNDANCY: start-on-event=GetEventEnableCondition, operation=EvtInfo_NVM_E_LOSS_OF_REDUNDANCY.GetEventEnableCondition
        OpEventGetEventEnableCondition_GetEventEnableCondition_EvtInfo_NVM_E_QUEUE_OVERFLOW: start-on-event=GetEventEnableCondition, operation=EvtInfo_NVM_E_QUEUE_OVERFLOW.GetEventEnableCondition
        OpEventGetEventEnableCondition_GetEventEnableCondition_EvtInfo_NVM_E_REQ_FAILED: start-on-event=GetEventEnableCondition, operation=EvtInfo_NVM_E_REQ_FAILED.GetEventEnableCondition
        OpEventGetEventEnableCondition_GetEventEnableCondition_EvtInfo_NVM_E_WRITE_PROTECTED: start-on-event=GetEventEnableCondition, operation=EvtInfo_NVM_E_WRITE_PROTECTED.GetEventEnableCondition
        OpEventGetEventEnableCondition_GetEventEnableCondition_EvtInfo_SPI_E_DATA_TX_TIMEOUT_FAILURE: start-on-event=GetEventEnableCondition, operation=EvtInfo_SPI_E_DATA_TX_TIMEOUT_FAILURE.GetEventEnableCondition
        OpEventGetEventEnableCondition_GetEventEnableCondition_EvtInfo_SPI_E_HARDWARE_ERROR: start-on-event=GetEventEnableCondition, operation=EvtInfo_SPI_E_HARDWARE_ERROR.GetEventEnableCondition
        OpEventGetEventEnableCondition_GetEventEnableCondition_EvtInfo_WDG_E_DISABLE_REJECTED: start-on-event=GetEventEnableCondition, operation=EvtInfo_WDG_E_DISABLE_REJECTED.GetEventEnableCondition
        OpEventGetEventEnableCondition_GetEventEnableCondition_EvtInfo_WDG_E_MODE_FAILED: start-on-event=GetEventEnableCondition, operation=EvtInfo_WDG_E_MODE_FAILED.GetEventEnableCondition
        OpEventGetEventEnableCondition_GetEventEnableCondition_EvtInfo_WDG_E_READBACK_FAILURE: start-on-event=GetEventEnableCondition, operation=EvtInfo_WDG_E_READBACK_FAILURE.GetEventEnableCondition
        OpEventGetDebouncingOfEvent_GetDebouncingOfEvent_EvtInfo_MCU_E_CLOCK_FAILURE: start-on-event=GetDebouncingOfEvent, operation=EvtInfo_MCU_E_CLOCK_FAILURE.GetDebouncingOfEvent
        OpEventGetDebouncingOfEvent_GetDebouncingOfEvent_EvtInfo_MCU_E_POWERDOWN_MODE_FAILURE: start-on-event=GetDebouncingOfEvent, operation=EvtInfo_MCU_E_POWERDOWN_MODE_FAILURE.GetDebouncingOfEvent
        OpEventGetDebouncingOfEvent_GetDebouncingOfEvent_EvtInfo_MCU_E_WRITE_TIMEOUT_FAILURE: start-on-event=GetDebouncingOfEvent, operation=EvtInfo_MCU_E_WRITE_TIMEOUT_FAILURE.GetDebouncingOfEvent
        OpEventGetDebouncingOfEvent_GetDebouncingOfEvent_EvtInfo_FLS_E_COMPARE_FAILED: start-on-event=GetDebouncingOfEvent, operation=EvtInfo_FLS_E_COMPARE_FAILED.GetDebouncingOfEvent
        OpEventGetDebouncingOfEvent_GetDebouncingOfEvent_EvtInfo_FLS_E_ERASE_FAILED: start-on-event=GetDebouncingOfEvent, operation=EvtInfo_FLS_E_ERASE_FAILED.GetDebouncingOfEvent
        OpEventGetDebouncingOfEvent_GetDebouncingOfEvent_EvtInfo_FLS_E_HW_FAILURE: start-on-event=GetDebouncingOfEvent, operation=EvtInfo_FLS_E_HW_FAILURE.GetDebouncingOfEvent
        OpEventGetDebouncingOfEvent_GetDebouncingOfEvent_EvtInfo_FLS_E_READ_FAILED: start-on-event=GetDebouncingOfEvent, operation=EvtInfo_FLS_E_READ_FAILED.GetDebouncingOfEvent
        OpEventGetDebouncingOfEvent_GetDebouncingOfEvent_EvtInfo_FLS_E_READ_FAILED_DED: start-on-event=GetDebouncingOfEvent, operation=EvtInfo_FLS_E_READ_FAILED_DED.GetDebouncingOfEvent
        OpEventGetDebouncingOfEvent_GetDebouncingOfEvent_EvtInfo_FLS_E_WRITE_FAILED: start-on-event=GetDebouncingOfEvent, operation=EvtInfo_FLS_E_WRITE_FAILED.GetDebouncingOfEvent
        OpEventGetDebouncingOfEvent_GetDebouncingOfEvent_EvtInfo_NVM_E_INTEGRITY_FAILED: start-on-event=GetDebouncingOfEvent, operation=EvtInfo_NVM_E_INTEGRITY_FAILED.GetDebouncingOfEvent
        OpEventGetDebouncingOfEvent_GetDebouncingOfEvent_EvtInfo_NVM_E_LOSS_OF_REDUNDANCY: start-on-event=GetDebouncingOfEvent, operation=EvtInfo_NVM_E_LOSS_OF_REDUNDANCY.GetDebouncingOfEvent
        OpEventGetDebouncingOfEvent_GetDebouncingOfEvent_EvtInfo_NVM_E_QUEUE_OVERFLOW: start-on-event=GetDebouncingOfEvent, operation=EvtInfo_NVM_E_QUEUE_OVERFLOW.GetDebouncingOfEvent
        OpEventGetDebouncingOfEvent_GetDebouncingOfEvent_EvtInfo_NVM_E_REQ_FAILED: start-on-event=GetDebouncingOfEvent, operation=EvtInfo_NVM_E_REQ_FAILED.GetDebouncingOfEvent
        OpEventGetDebouncingOfEvent_GetDebouncingOfEvent_EvtInfo_NVM_E_WRITE_PROTECTED: start-on-event=GetDebouncingOfEvent, operation=EvtInfo_NVM_E_WRITE_PROTECTED.GetDebouncingOfEvent
        OpEventGetDebouncingOfEvent_GetDebouncingOfEvent_EvtInfo_SPI_E_DATA_TX_TIMEOUT_FAILURE: start-on-event=GetDebouncingOfEvent, operation=EvtInfo_SPI_E_DATA_TX_TIMEOUT_FAILURE.GetDebouncingOfEvent
        OpEventGetDebouncingOfEvent_GetDebouncingOfEvent_EvtInfo_SPI_E_HARDWARE_ERROR: start-on-event=GetDebouncingOfEvent, operation=EvtInfo_SPI_E_HARDWARE_ERROR.GetDebouncingOfEvent
        OpEventGetDebouncingOfEvent_GetDebouncingOfEvent_EvtInfo_WDG_E_DISABLE_REJECTED: start-on-event=GetDebouncingOfEvent, operation=EvtInfo_WDG_E_DISABLE_REJECTED.GetDebouncingOfEvent
        OpEventGetDebouncingOfEvent_GetDebouncingOfEvent_EvtInfo_WDG_E_MODE_FAILED: start-on-event=GetDebouncingOfEvent, operation=EvtInfo_WDG_E_MODE_FAILED.GetDebouncingOfEvent
        OpEventGetDebouncingOfEvent_GetDebouncingOfEvent_EvtInfo_WDG_E_READBACK_FAILURE: start-on-event=GetDebouncingOfEvent, operation=EvtInfo_WDG_E_READBACK_FAILURE.GetDebouncingOfEvent
        OpEventSetOperationCycleState_SetOperationCycleState_OpCycle_IgnitionCycle: start-on-event=SetOperationCycleState, operation=OpCycle_IgnitionCycle.SetOperationCycleState
        OpEventSetOperationCycleState_SetOperationCycleState_OpCycle_PowerCycle: start-on-event=SetOperationCycleState, operation=OpCycle_PowerCycle.SetOperationCycleState
        OpEventGetEventStatus_GetEventStatus_EvtInfo_DIO_E_REG_WRITE_VERIFY: start-on-event=GetEventStatus, operation=EvtInfo_DIO_E_REG_WRITE_VERIFY.GetEventStatus
        OpEventGetEventFailed_GetEventFailed_EvtInfo_DIO_E_REG_WRITE_VERIFY: start-on-event=GetEventFailed, operation=EvtInfo_DIO_E_REG_WRITE_VERIFY.GetEventFailed
        OpEventGetEventTested_GetEventTested_EvtInfo_DIO_E_REG_WRITE_VERIFY: start-on-event=GetEventTested, operation=EvtInfo_DIO_E_REG_WRITE_VERIFY.GetEventTested
        OpEventGetDTCOfEvent_GetDTCOfEvent_EvtInfo_DIO_E_REG_WRITE_VERIFY: start-on-event=GetDTCOfEvent, operation=EvtInfo_DIO_E_REG_WRITE_VERIFY.GetDTCOfEvent
        OpEventGetFaultDetectionCounter_GetFaultDetectionCounter_EvtInfo_DIO_E_REG_WRITE_VERIFY: start-on-event=GetFaultDetectionCounter, operation=EvtInfo_DIO_E_REG_WRITE_VERIFY.GetFaultDetectionCounter
        OpEventGetEventFreezeFrameData_GetEventFreezeFrameData_EvtInfo_DIO_E_REG_WRITE_VERIFY: start-on-event=GetEventFreezeFrameData, operation=EvtInfo_DIO_E_REG_WRITE_VERIFY.GetEventFreezeFrameData
        OpEventGetEventExtendedDataRecord_GetEventExtendedDataRecord_EvtInfo_DIO_E_REG_WRITE_VERIFY: start-on-event=GetEventExtendedDataRecord, operation=EvtInfo_DIO_E_REG_WRITE_VERIFY.GetEventExtendedDataRecord
        OpEventGetEventEnableCondition_GetEventEnableCondition_EvtInfo_DIO_E_REG_WRITE_VERIFY: start-on-event=GetEventEnableCondition, operation=EvtInfo_DIO_E_REG_WRITE_VERIFY.GetEventEnableCondition
        OpEventGetDebouncingOfEvent_GetDebouncingOfEvent_EvtInfo_DIO_E_REG_WRITE_VERIFY: start-on-event=GetDebouncingOfEvent, operation=EvtInfo_DIO_E_REG_WRITE_VERIFY.GetDebouncingOfEvent
        OpEventGetEventStatus_GetEventStatus_EvtInfo_PORT_E_REG_WRITE_VERIFY: start-on-event=GetEventStatus, operation=EvtInfo_PORT_E_REG_WRITE_VERIFY.GetEventStatus
        OpEventGetEventFailed_GetEventFailed_EvtInfo_PORT_E_REG_WRITE_VERIFY: start-on-event=GetEventFailed, operation=EvtInfo_PORT_E_REG_WRITE_VERIFY.GetEventFailed
        OpEventGetEventTested_GetEventTested_EvtInfo_PORT_E_REG_WRITE_VERIFY: start-on-event=GetEventTested, operation=EvtInfo_PORT_E_REG_WRITE_VERIFY.GetEventTested
        OpEventGetDTCOfEvent_GetDTCOfEvent_EvtInfo_PORT_E_REG_WRITE_VERIFY: start-on-event=GetDTCOfEvent, operation=EvtInfo_PORT_E_REG_WRITE_VERIFY.GetDTCOfEvent
        OpEventGetFaultDetectionCounter_GetFaultDetectionCounter_EvtInfo_PORT_E_REG_WRITE_VERIFY: start-on-event=GetFaultDetectionCounter, operation=EvtInfo_PORT_E_REG_WRITE_VERIFY.GetFaultDetectionCounter
        OpEventGetEventFreezeFrameData_GetEventFreezeFrameData_EvtInfo_PORT_E_REG_WRITE_VERIFY: start-on-event=GetEventFreezeFrameData, operation=EvtInfo_PORT_E_REG_WRITE_VERIFY.GetEventFreezeFrameData
        OpEventGetEventExtendedDataRecord_GetEventExtendedDataRecord_EvtInfo_PORT_E_REG_WRITE_VERIFY: start-on-event=GetEventExtendedDataRecord, operation=EvtInfo_PORT_E_REG_WRITE_VERIFY.GetEventExtendedDataRecord
        OpEventGetEventEnableCondition_GetEventEnableCondition_EvtInfo_PORT_E_REG_WRITE_VERIFY: start-on-event=GetEventEnableCondition, operation=EvtInfo_PORT_E_REG_WRITE_VERIFY.GetEventEnableCondition
        OpEventGetDebouncingOfEvent_GetDebouncingOfEvent_EvtInfo_PORT_E_REG_WRITE_VERIFY: start-on-event=GetDebouncingOfEvent, operation=EvtInfo_PORT_E_REG_WRITE_VERIFY.GetDebouncingOfEvent
        OpEventGetEventStatus_GetEventStatus_EvtInfo_DTC_0x600b62: start-on-event=GetEventStatus, operation=EvtInfo_DTC_0x600b62.GetEventStatus
        OpEventGetEventStatus_GetEventStatus_Event_DTC_0x600b62: start-on-event=GetEventStatus, operation=Event_DTC_0x600b62.GetEventStatus
        OpEventGetEventStatus_GetEventStatus_EvtInfo_DTC_0xc25600: start-on-event=GetEventStatus, operation=EvtInfo_DTC_0xc25600.GetEventStatus
        OpEventGetEventStatus_GetEventStatus_Event_DTC_0xc25600: start-on-event=GetEventStatus, operation=Event_DTC_0xc25600.GetEventStatus
        OpEventGetEventStatus_GetEventStatus_EvtInfo_DTC_0xf00049: start-on-event=GetEventStatus, operation=EvtInfo_DTC_0xf00049.GetEventStatus
        OpEventGetEventStatus_GetEventStatus_Event_DTC_0xf00049: start-on-event=GetEventStatus, operation=Event_DTC_0xf00049.GetEventStatus
        OpEventGetEventStatus_GetEventStatus_EvtInfo_DTC_0xe10000: start-on-event=GetEventStatus, operation=EvtInfo_DTC_0xe10000.GetEventStatus
        OpEventGetEventStatus_GetEventStatus_Event_DTC_0xe10000: start-on-event=GetEventStatus, operation=Event_DTC_0xe10000.GetEventStatus
        OpEventGetEventStatus_GetEventStatus_EvtInfo_DTC_0xf00168: start-on-event=GetEventStatus, operation=EvtInfo_DTC_0xf00168.GetEventStatus
        OpEventGetEventStatus_GetEventStatus_Event_DTC_0xf00168: start-on-event=GetEventStatus, operation=Event_DTC_0xf00168.GetEventStatus
        OpEventGetEventStatus_GetEventStatus_EvtInfo_DTC_0xf00042: start-on-event=GetEventStatus, operation=EvtInfo_DTC_0xf00042.GetEventStatus
        OpEventGetEventStatus_GetEventStatus_Event_DTC_0xf00042: start-on-event=GetEventStatus, operation=Event_DTC_0xf00042.GetEventStatus
        OpEventGetEventStatus_GetEventStatus_EvtInfo_DTC_0xc25200: start-on-event=GetEventStatus, operation=EvtInfo_DTC_0xc25200.GetEventStatus
        OpEventGetEventStatus_GetEventStatus_Event_DTC_0xc25200: start-on-event=GetEventStatus, operation=Event_DTC_0xc25200.GetEventStatus
        OpEventGetEventStatus_GetEventStatus_EvtInfo_DTC_0xe01492: start-on-event=GetEventStatus, operation=EvtInfo_DTC_0xe01492.GetEventStatus
        OpEventGetEventStatus_GetEventStatus_Event_DTC_0xe01492: start-on-event=GetEventStatus, operation=Event_DTC_0xe01492.GetEventStatus
        OpEventGetEventStatus_GetEventStatus_EvtInfo_DTC_0xc41522: start-on-event=GetEventStatus, operation=EvtInfo_DTC_0xc41522.GetEventStatus
        OpEventGetEventStatus_GetEventStatus_Event_DTC_0xc41522: start-on-event=GetEventStatus, operation=Event_DTC_0xc41522.GetEventStatus
        OpEventGetEventStatus_GetEventStatus_EvtInfo_DTC_0xc55700: start-on-event=GetEventStatus, operation=EvtInfo_DTC_0xc55700.GetEventStatus
        OpEventGetEventStatus_GetEventStatus_Event_DTC_0xc55700: start-on-event=GetEventStatus, operation=Event_DTC_0xc55700.GetEventStatus
        OpEventGetEventStatus_GetEventStatus_EvtInfo_DTC_0xc55300: start-on-event=GetEventStatus, operation=EvtInfo_DTC_0xc55300.GetEventStatus
        OpEventGetEventStatus_GetEventStatus_Event_DTC_0xc55300: start-on-event=GetEventStatus, operation=Event_DTC_0xc55300.GetEventStatus
        OpEventGetEventStatus_GetEventStatus_EvtInfo_DTC_0x5b0062: start-on-event=GetEventStatus, operation=EvtInfo_DTC_0x5b0062.GetEventStatus
        OpEventGetEventStatus_GetEventStatus_Event_DTC_0x5b0062: start-on-event=GetEventStatus, operation=Event_DTC_0x5b0062.GetEventStatus
        OpEventGetEventStatus_GetEventStatus_EvtInfo_DTC_0x511056: start-on-event=GetEventStatus, operation=EvtInfo_DTC_0x511056.GetEventStatus
        OpEventGetEventStatus_GetEventStatus_Event_DTC_0x511056: start-on-event=GetEventStatus, operation=Event_DTC_0x511056.GetEventStatus
        OpEventGetEventStatus_GetEventStatus_EvtInfo_DTC_0xc10000: start-on-event=GetEventStatus, operation=EvtInfo_DTC_0xc10000.GetEventStatus
        OpEventGetEventStatus_GetEventStatus_Event_DTC_0xc10000: start-on-event=GetEventStatus, operation=Event_DTC_0xc10000.GetEventStatus
        OpEventGetEventStatus_GetEventStatus_EvtInfo_DTC_0xe01481: start-on-event=GetEventStatus, operation=EvtInfo_DTC_0xe01481.GetEventStatus
        OpEventGetEventStatus_GetEventStatus_Event_DTC_0xe01481: start-on-event=GetEventStatus, operation=Event_DTC_0xe01481.GetEventStatus
        OpEventGetEventStatus_GetEventStatus_EvtInfo_DTC_0xc14600: start-on-event=GetEventStatus, operation=EvtInfo_DTC_0xc14600.GetEventStatus
        OpEventGetEventStatus_GetEventStatus_Event_DTC_0xc14600: start-on-event=GetEventStatus, operation=Event_DTC_0xc14600.GetEventStatus
        OpEventGetEventStatus_GetEventStatus_EvtInfo_DTC_0xe01647: start-on-event=GetEventStatus, operation=EvtInfo_DTC_0xe01647.GetEventStatus
        OpEventGetEventStatus_GetEventStatus_Event_DTC_0xe01647: start-on-event=GetEventStatus, operation=Event_DTC_0xe01647.GetEventStatus
        OpEventGetEventStatus_GetEventStatus_EvtInfo_DTC_0xe01648: start-on-event=GetEventStatus, operation=EvtInfo_DTC_0xe01648.GetEventStatus
        OpEventGetEventStatus_GetEventStatus_Event_DTC_0xe01648: start-on-event=GetEventStatus, operation=Event_DTC_0xe01648.GetEventStatus
        OpEventGetEventStatus_GetEventStatus_EvtInfo_DTC_0xc40100: start-on-event=GetEventStatus, operation=EvtInfo_DTC_0xc40100.GetEventStatus
        OpEventGetEventStatus_GetEventStatus_Event_DTC_0xc40100: start-on-event=GetEventStatus, operation=Event_DTC_0xc40100.GetEventStatus
        OpEventGetEventStatus_GetEventStatus_EvtInfo_DTC_0xc53b00: start-on-event=GetEventStatus, operation=EvtInfo_DTC_0xc53b00.GetEventStatus
        OpEventGetEventStatus_GetEventStatus_Event_DTC_0xc53b00: start-on-event=GetEventStatus, operation=Event_DTC_0xc53b00.GetEventStatus
        OpEventGetEventStatus_GetEventStatus_EvtInfo_DTC_0xf00061: start-on-event=GetEventStatus, operation=EvtInfo_DTC_0xf00061.GetEventStatus
        OpEventGetEventStatus_GetEventStatus_Event_DTC_0xf00061: start-on-event=GetEventStatus, operation=Event_DTC_0xf00061.GetEventStatus
        OpEventGetEventStatus_GetEventStatus_EvtInfo_DTC_0x600d49: start-on-event=GetEventStatus, operation=EvtInfo_DTC_0x600d49.GetEventStatus
        OpEventGetEventStatus_GetEventStatus_Event_DTC_0x600d49: start-on-event=GetEventStatus, operation=Event_DTC_0x600d49.GetEventStatus
        OpEventGetEventStatus_GetEventStatus_EvtInfo_DTC_0xc55400: start-on-event=GetEventStatus, operation=EvtInfo_DTC_0xc55400.GetEventStatus
        OpEventGetEventStatus_GetEventStatus_Event_DTC_0xc55400: start-on-event=GetEventStatus, operation=Event_DTC_0xc55400.GetEventStatus
        OpEventGetEventStatus_GetEventStatus_EvtInfo_DTC_0xe01478: start-on-event=GetEventStatus, operation=EvtInfo_DTC_0xe01478.GetEventStatus
        OpEventGetEventStatus_GetEventStatus_Event_DTC_0xe01478: start-on-event=GetEventStatus, operation=Event_DTC_0xe01478.GetEventStatus
        OpEventGetEventStatus_GetEventStatus_EvtInfo_DTC_0x502d00: start-on-event=GetEventStatus, operation=EvtInfo_DTC_0x502d00.GetEventStatus
        OpEventGetEventStatus_GetEventStatus_Event_DTC_0x502d00: start-on-event=GetEventStatus, operation=Event_DTC_0x502d00.GetEventStatus
        OpEventGetEventStatus_GetEventStatus_EvtInfo_DTC_0xc12200: start-on-event=GetEventStatus, operation=EvtInfo_DTC_0xc12200.GetEventStatus
        OpEventGetEventStatus_GetEventStatus_Event_DTC_0xc12200: start-on-event=GetEventStatus, operation=Event_DTC_0xc12200.GetEventStatus
        OpEventGetEventStatus_GetEventStatus_EvtInfo_DTC_0xc12600: start-on-event=GetEventStatus, operation=EvtInfo_DTC_0xc12600.GetEventStatus
        OpEventGetEventStatus_GetEventStatus_Event_DTC_0xc12600: start-on-event=GetEventStatus, operation=Event_DTC_0xc12600.GetEventStatus
        OpEventGetEventStatus_GetEventStatus_EvtInfo_DTC_0xf00368: start-on-event=GetEventStatus, operation=EvtInfo_DTC_0xf00368.GetEventStatus
        OpEventGetEventStatus_GetEventStatus_Event_DTC_0xf00368: start-on-event=GetEventStatus, operation=Event_DTC_0xf00368.GetEventStatus
        OpEventGetEventStatus_GetEventStatus_EvtInfo_DTC_0x600d62: start-on-event=GetEventStatus, operation=EvtInfo_DTC_0x600d62.GetEventStatus
        OpEventGetEventStatus_GetEventStatus_Event_DTC_0x600d62: start-on-event=GetEventStatus, operation=Event_DTC_0x600d62.GetEventStatus
        OpEventGetEventStatus_GetEventStatus_EvtInfo_DTC_0xc42300: start-on-event=GetEventStatus, operation=EvtInfo_DTC_0xc42300.GetEventStatus
        OpEventGetEventStatus_GetEventStatus_Event_DTC_0xc42300: start-on-event=GetEventStatus, operation=Event_DTC_0xc42300.GetEventStatus
        OpEventGetEventStatus_GetEventStatus_EvtInfo_DTC_0xc53c00: start-on-event=GetEventStatus, operation=EvtInfo_DTC_0xc53c00.GetEventStatus
        OpEventGetEventStatus_GetEventStatus_Event_DTC_0xc53c00: start-on-event=GetEventStatus, operation=Event_DTC_0xc53c00.GetEventStatus
        OpEventGetEventStatus_GetEventStatus_EvtInfo_DTC_0xe30055: start-on-event=GetEventStatus, operation=EvtInfo_DTC_0xe30055.GetEventStatus
        OpEventGetEventStatus_GetEventStatus_Event_DTC_0xe30055: start-on-event=GetEventStatus, operation=Event_DTC_0xe30055.GetEventStatus
        OpEventGetEventStatus_GetEventStatus_EvtInfo_DTC_0x600c49: start-on-event=GetEventStatus, operation=EvtInfo_DTC_0x600c49.GetEventStatus
        OpEventGetEventStatus_GetEventStatus_Event_DTC_0x600c49: start-on-event=GetEventStatus, operation=Event_DTC_0x600c49.GetEventStatus
        OpEventGetEventStatus_GetEventStatus_EvtInfo_DTC_0xc23b00: start-on-event=GetEventStatus, operation=EvtInfo_DTC_0xc23b00.GetEventStatus
        OpEventGetEventStatus_GetEventStatus_Event_DTC_0xc23b00: start-on-event=GetEventStatus, operation=Event_DTC_0xc23b00.GetEventStatus
        OpEventGetEventStatus_GetEventStatus_EvtInfo_DTC_0xc41600: start-on-event=GetEventStatus, operation=EvtInfo_DTC_0xc41600.GetEventStatus
        OpEventGetEventStatus_GetEventStatus_Event_DTC_0xc41600: start-on-event=GetEventStatus, operation=Event_DTC_0xc41600.GetEventStatus
        OpEventGetEventStatus_GetEventStatus_EvtInfo_DTC_0x9d234b: start-on-event=GetEventStatus, operation=EvtInfo_DTC_0x9d234b.GetEventStatus
        OpEventGetEventStatus_GetEventStatus_Event_DTC_0x9d234b: start-on-event=GetEventStatus, operation=Event_DTC_0x9d234b.GetEventStatus
        OpEventGetEventStatus_GetEventStatus_EvtInfo_DTC_0xc10200: start-on-event=GetEventStatus, operation=EvtInfo_DTC_0xc10200.GetEventStatus
        OpEventGetEventStatus_GetEventStatus_Event_DTC_0xc10200: start-on-event=GetEventStatus, operation=Event_DTC_0xc10200.GetEventStatus
        OpEventGetEventStatus_GetEventStatus_EvtInfo_DTC_0xc12100: start-on-event=GetEventStatus, operation=EvtInfo_DTC_0xc12100.GetEventStatus
        OpEventGetEventStatus_GetEventStatus_Event_DTC_0xc12100: start-on-event=GetEventStatus, operation=Event_DTC_0xc12100.GetEventStatus
        OpEventGetEventStatus_GetEventStatus_EvtInfo_DTC_0xc42800: start-on-event=GetEventStatus, operation=EvtInfo_DTC_0xc42800.GetEventStatus
        OpEventGetEventStatus_GetEventStatus_Event_DTC_0xc42800: start-on-event=GetEventStatus, operation=Event_DTC_0xc42800.GetEventStatus
        OpEventGetEventStatus_GetEventStatus_EvtInfo_DTC_0xc14000: start-on-event=GetEventStatus, operation=EvtInfo_DTC_0xc14000.GetEventStatus
        OpEventGetEventStatus_GetEventStatus_Event_DTC_0xc14000: start-on-event=GetEventStatus, operation=Event_DTC_0xc14000.GetEventStatus
        OpEventGetEventStatus_GetEventStatus_EvtInfo_DTC_0xc45a00: start-on-event=GetEventStatus, operation=EvtInfo_DTC_0xc45a00.GetEventStatus
        OpEventGetEventStatus_GetEventStatus_Event_DTC_0xc45a00: start-on-event=GetEventStatus, operation=Event_DTC_0xc45a00.GetEventStatus
        OpEventGetEventStatus_GetEventStatus_EvtInfo_DTC_0xc25300: start-on-event=GetEventStatus, operation=EvtInfo_DTC_0xc25300.GetEventStatus
        OpEventGetEventStatus_GetEventStatus_Event_DTC_0xc25300: start-on-event=GetEventStatus, operation=Event_DTC_0xc25300.GetEventStatus
        OpEventGetEventStatus_GetEventStatus_EvtInfo_DTC_0x600c62: start-on-event=GetEventStatus, operation=EvtInfo_DTC_0x600c62.GetEventStatus
        OpEventGetEventStatus_GetEventStatus_Event_DTC_0x600c62: start-on-event=GetEventStatus, operation=Event_DTC_0x600c62.GetEventStatus
        OpEventGetEventStatus_GetEventStatus_EvtInfo_DTC_0xc42200: start-on-event=GetEventStatus, operation=EvtInfo_DTC_0xc42200.GetEventStatus
        OpEventGetEventStatus_GetEventStatus_Event_DTC_0xc42200: start-on-event=GetEventStatus, operation=Event_DTC_0xc42200.GetEventStatus
        OpEventGetEventStatus_GetEventStatus_EvtInfo_DTC_0xc40300: start-on-event=GetEventStatus, operation=EvtInfo_DTC_0xc40300.GetEventStatus
        OpEventGetEventStatus_GetEventStatus_Event_DTC_0xc40300: start-on-event=GetEventStatus, operation=Event_DTC_0xc40300.GetEventStatus
        OpEventGetEventStatus_GetEventStatus_EvtInfo_DTC_0x600b49: start-on-event=GetEventStatus, operation=EvtInfo_DTC_0x600b49.GetEventStatus
        OpEventGetEventStatus_GetEventStatus_Event_DTC_0x600b49: start-on-event=GetEventStatus, operation=Event_DTC_0x600b49.GetEventStatus
        OpEventGetEventStatus_GetEventStatus_EvtInfo_DTC_0xc15900: start-on-event=GetEventStatus, operation=EvtInfo_DTC_0xc15900.GetEventStatus
        OpEventGetEventStatus_GetEventStatus_Event_DTC_0xc15900: start-on-event=GetEventStatus, operation=Event_DTC_0xc15900.GetEventStatus
        OpEventGetEventStatus_GetEventStatus_EvtInfo_DTC_0xc23a00: start-on-event=GetEventStatus, operation=EvtInfo_DTC_0xc23a00.GetEventStatus
        OpEventGetEventStatus_GetEventStatus_Event_DTC_0xc23a00: start-on-event=GetEventStatus, operation=Event_DTC_0xc23a00.GetEventStatus
        OpEventGetEventStatus_GetEventStatus_EvtInfo_DTC_0xc15500: start-on-event=GetEventStatus, operation=EvtInfo_DTC_0xc15500.GetEventStatus
        OpEventGetEventStatus_GetEventStatus_Event_DTC_0xc15500: start-on-event=GetEventStatus, operation=Event_DTC_0xc15500.GetEventStatus
        OpEventGetEventStatus_GetEventStatus_EvtInfo_DTC_0xc41500: start-on-event=GetEventStatus, operation=EvtInfo_DTC_0xc41500.GetEventStatus
        OpEventGetEventStatus_GetEventStatus_Event_DTC_0xc41500: start-on-event=GetEventStatus, operation=Event_DTC_0xc41500.GetEventStatus
        OpEventGetEventStatus_GetEventStatus_EvtInfo_DTC_0x5b0049: start-on-event=GetEventStatus, operation=EvtInfo_DTC_0x5b0049.GetEventStatus
        OpEventGetEventStatus_GetEventStatus_Event_DTC_0x5b0049: start-on-event=GetEventStatus, operation=Event_DTC_0x5b0049.GetEventStatus
        OpEventGetEventStatus_GetEventStatus_EvtInfo_DTC_0xf00317: start-on-event=GetEventStatus, operation=EvtInfo_DTC_0xf00317.GetEventStatus
        OpEventGetEventStatus_GetEventStatus_Event_DTC_0xf00317: start-on-event=GetEventStatus, operation=Event_DTC_0xf00317.GetEventStatus
        OpEventGetEventStatus_GetEventStatus_EvtInfo_DTC_0xf00316: start-on-event=GetEventStatus, operation=EvtInfo_DTC_0xf00316.GetEventStatus
        OpEventGetEventStatus_GetEventStatus_Event_DTC_0xf00316: start-on-event=GetEventStatus, operation=Event_DTC_0xf00316.GetEventStatus
        OpEventGetEventFailed_GetEventFailed_EvtInfo_DTC_0x600b62: start-on-event=GetEventFailed, operation=EvtInfo_DTC_0x600b62.GetEventFailed
        OpEventGetEventFailed_GetEventFailed_Event_DTC_0x600b62: start-on-event=GetEventFailed, operation=Event_DTC_0x600b62.GetEventFailed
        OpEventGetEventFailed_GetEventFailed_EvtInfo_DTC_0xc25600: start-on-event=GetEventFailed, operation=EvtInfo_DTC_0xc25600.GetEventFailed
        OpEventGetEventFailed_GetEventFailed_Event_DTC_0xc25600: start-on-event=GetEventFailed, operation=Event_DTC_0xc25600.GetEventFailed
        OpEventGetEventFailed_GetEventFailed_EvtInfo_DTC_0xf00049: start-on-event=GetEventFailed, operation=EvtInfo_DTC_0xf00049.GetEventFailed
        OpEventGetEventFailed_GetEventFailed_Event_DTC_0xf00049: start-on-event=GetEventFailed, operation=Event_DTC_0xf00049.GetEventFailed
        OpEventGetEventFailed_GetEventFailed_EvtInfo_DTC_0xe10000: start-on-event=GetEventFailed, operation=EvtInfo_DTC_0xe10000.GetEventFailed
        OpEventGetEventFailed_GetEventFailed_Event_DTC_0xe10000: start-on-event=GetEventFailed, operation=Event_DTC_0xe10000.GetEventFailed
        OpEventGetEventFailed_GetEventFailed_EvtInfo_DTC_0xf00168: start-on-event=GetEventFailed, operation=EvtInfo_DTC_0xf00168.GetEventFailed
        OpEventGetEventFailed_GetEventFailed_Event_DTC_0xf00168: start-on-event=GetEventFailed, operation=Event_DTC_0xf00168.GetEventFailed
        OpEventGetEventFailed_GetEventFailed_EvtInfo_DTC_0xf00042: start-on-event=GetEventFailed, operation=EvtInfo_DTC_0xf00042.GetEventFailed
        OpEventGetEventFailed_GetEventFailed_Event_DTC_0xf00042: start-on-event=GetEventFailed, operation=Event_DTC_0xf00042.GetEventFailed
        OpEventGetEventFailed_GetEventFailed_EvtInfo_DTC_0xc25200: start-on-event=GetEventFailed, operation=EvtInfo_DTC_0xc25200.GetEventFailed
        OpEventGetEventFailed_GetEventFailed_Event_DTC_0xc25200: start-on-event=GetEventFailed, operation=Event_DTC_0xc25200.GetEventFailed
        OpEventGetEventFailed_GetEventFailed_EvtInfo_DTC_0xe01492: start-on-event=GetEventFailed, operation=EvtInfo_DTC_0xe01492.GetEventFailed
        OpEventGetEventFailed_GetEventFailed_Event_DTC_0xe01492: start-on-event=GetEventFailed, operation=Event_DTC_0xe01492.GetEventFailed
        OpEventGetEventFailed_GetEventFailed_EvtInfo_DTC_0xc41522: start-on-event=GetEventFailed, operation=EvtInfo_DTC_0xc41522.GetEventFailed
        OpEventGetEventFailed_GetEventFailed_Event_DTC_0xc41522: start-on-event=GetEventFailed, operation=Event_DTC_0xc41522.GetEventFailed
        OpEventGetEventFailed_GetEventFailed_EvtInfo_DTC_0xc55700: start-on-event=GetEventFailed, operation=EvtInfo_DTC_0xc55700.GetEventFailed
        OpEventGetEventFailed_GetEventFailed_Event_DTC_0xc55700: start-on-event=GetEventFailed, operation=Event_DTC_0xc55700.GetEventFailed
        OpEventGetEventFailed_GetEventFailed_EvtInfo_DTC_0xc55300: start-on-event=GetEventFailed, operation=EvtInfo_DTC_0xc55300.GetEventFailed
        OpEventGetEventFailed_GetEventFailed_Event_DTC_0xc55300: start-on-event=GetEventFailed, operation=Event_DTC_0xc55300.GetEventFailed
        OpEventGetEventFailed_GetEventFailed_EvtInfo_DTC_0x5b0062: start-on-event=GetEventFailed, operation=EvtInfo_DTC_0x5b0062.GetEventFailed
        OpEventGetEventFailed_GetEventFailed_Event_DTC_0x5b0062: start-on-event=GetEventFailed, operation=Event_DTC_0x5b0062.GetEventFailed
        OpEventGetEventFailed_GetEventFailed_EvtInfo_DTC_0x511056: start-on-event=GetEventFailed, operation=EvtInfo_DTC_0x511056.GetEventFailed
        OpEventGetEventFailed_GetEventFailed_Event_DTC_0x511056: start-on-event=GetEventFailed, operation=Event_DTC_0x511056.GetEventFailed
        OpEventGetEventFailed_GetEventFailed_EvtInfo_DTC_0xc10000: start-on-event=GetEventFailed, operation=EvtInfo_DTC_0xc10000.GetEventFailed
        OpEventGetEventFailed_GetEventFailed_Event_DTC_0xc10000: start-on-event=GetEventFailed, operation=Event_DTC_0xc10000.GetEventFailed
        OpEventGetEventFailed_GetEventFailed_EvtInfo_DTC_0xe01481: start-on-event=GetEventFailed, operation=EvtInfo_DTC_0xe01481.GetEventFailed
        OpEventGetEventFailed_GetEventFailed_Event_DTC_0xe01481: start-on-event=GetEventFailed, operation=Event_DTC_0xe01481.GetEventFailed
        OpEventGetEventFailed_GetEventFailed_EvtInfo_DTC_0xc14600: start-on-event=GetEventFailed, operation=EvtInfo_DTC_0xc14600.GetEventFailed
        OpEventGetEventFailed_GetEventFailed_Event_DTC_0xc14600: start-on-event=GetEventFailed, operation=Event_DTC_0xc14600.GetEventFailed
        OpEventGetEventFailed_GetEventFailed_EvtInfo_DTC_0xe01647: start-on-event=GetEventFailed, operation=EvtInfo_DTC_0xe01647.GetEventFailed
        OpEventGetEventFailed_GetEventFailed_Event_DTC_0xe01647: start-on-event=GetEventFailed, operation=Event_DTC_0xe01647.GetEventFailed
        OpEventGetEventFailed_GetEventFailed_EvtInfo_DTC_0xe01648: start-on-event=GetEventFailed, operation=EvtInfo_DTC_0xe01648.GetEventFailed
        OpEventGetEventFailed_GetEventFailed_Event_DTC_0xe01648: start-on-event=GetEventFailed, operation=Event_DTC_0xe01648.GetEventFailed
        OpEventGetEventFailed_GetEventFailed_EvtInfo_DTC_0xc40100: start-on-event=GetEventFailed, operation=EvtInfo_DTC_0xc40100.GetEventFailed
        OpEventGetEventFailed_GetEventFailed_Event_DTC_0xc40100: start-on-event=GetEventFailed, operation=Event_DTC_0xc40100.GetEventFailed
        OpEventGetEventFailed_GetEventFailed_EvtInfo_DTC_0xc53b00: start-on-event=GetEventFailed, operation=EvtInfo_DTC_0xc53b00.GetEventFailed
        OpEventGetEventFailed_GetEventFailed_Event_DTC_0xc53b00: start-on-event=GetEventFailed, operation=Event_DTC_0xc53b00.GetEventFailed
        OpEventGetEventFailed_GetEventFailed_EvtInfo_DTC_0xf00061: start-on-event=GetEventFailed, operation=EvtInfo_DTC_0xf00061.GetEventFailed
        OpEventGetEventFailed_GetEventFailed_Event_DTC_0xf00061: start-on-event=GetEventFailed, operation=Event_DTC_0xf00061.GetEventFailed
        OpEventGetEventFailed_GetEventFailed_EvtInfo_DTC_0x600d49: start-on-event=GetEventFailed, operation=EvtInfo_DTC_0x600d49.GetEventFailed
        OpEventGetEventFailed_GetEventFailed_Event_DTC_0x600d49: start-on-event=GetEventFailed, operation=Event_DTC_0x600d49.GetEventFailed
        OpEventGetEventFailed_GetEventFailed_EvtInfo_DTC_0xc55400: start-on-event=GetEventFailed, operation=EvtInfo_DTC_0xc55400.GetEventFailed
        OpEventGetEventFailed_GetEventFailed_Event_DTC_0xc55400: start-on-event=GetEventFailed, operation=Event_DTC_0xc55400.GetEventFailed
        OpEventGetEventFailed_GetEventFailed_EvtInfo_DTC_0xe01478: start-on-event=GetEventFailed, operation=EvtInfo_DTC_0xe01478.GetEventFailed
        OpEventGetEventFailed_GetEventFailed_Event_DTC_0xe01478: start-on-event=GetEventFailed, operation=Event_DTC_0xe01478.GetEventFailed
        OpEventGetEventFailed_GetEventFailed_EvtInfo_DTC_0x502d00: start-on-event=GetEventFailed, operation=EvtInfo_DTC_0x502d00.GetEventFailed
        OpEventGetEventFailed_GetEventFailed_Event_DTC_0x502d00: start-on-event=GetEventFailed, operation=Event_DTC_0x502d00.GetEventFailed
        OpEventGetEventFailed_GetEventFailed_EvtInfo_DTC_0xc12200: start-on-event=GetEventFailed, operation=EvtInfo_DTC_0xc12200.GetEventFailed
        OpEventGetEventFailed_GetEventFailed_Event_DTC_0xc12200: start-on-event=GetEventFailed, operation=Event_DTC_0xc12200.GetEventFailed
        OpEventGetEventFailed_GetEventFailed_EvtInfo_DTC_0xc12600: start-on-event=GetEventFailed, operation=EvtInfo_DTC_0xc12600.GetEventFailed
        OpEventGetEventFailed_GetEventFailed_Event_DTC_0xc12600: start-on-event=GetEventFailed, operation=Event_DTC_0xc12600.GetEventFailed
        OpEventGetEventFailed_GetEventFailed_EvtInfo_DTC_0xf00368: start-on-event=GetEventFailed, operation=EvtInfo_DTC_0xf00368.GetEventFailed
        OpEventGetEventFailed_GetEventFailed_Event_DTC_0xf00368: start-on-event=GetEventFailed, operation=Event_DTC_0xf00368.GetEventFailed
        OpEventGetEventFailed_GetEventFailed_EvtInfo_DTC_0x600d62: start-on-event=GetEventFailed, operation=EvtInfo_DTC_0x600d62.GetEventFailed
        OpEventGetEventFailed_GetEventFailed_Event_DTC_0x600d62: start-on-event=GetEventFailed, operation=Event_DTC_0x600d62.GetEventFailed
        OpEventGetEventFailed_GetEventFailed_EvtInfo_DTC_0xc42300: start-on-event=GetEventFailed, operation=EvtInfo_DTC_0xc42300.GetEventFailed
        OpEventGetEventFailed_GetEventFailed_Event_DTC_0xc42300: start-on-event=GetEventFailed, operation=Event_DTC_0xc42300.GetEventFailed
        OpEventGetEventFailed_GetEventFailed_EvtInfo_DTC_0xc53c00: start-on-event=GetEventFailed, operation=EvtInfo_DTC_0xc53c00.GetEventFailed
        OpEventGetEventFailed_GetEventFailed_Event_DTC_0xc53c00: start-on-event=GetEventFailed, operation=Event_DTC_0xc53c00.GetEventFailed
        OpEventGetEventFailed_GetEventFailed_EvtInfo_DTC_0xe30055: start-on-event=GetEventFailed, operation=EvtInfo_DTC_0xe30055.GetEventFailed
        OpEventGetEventFailed_GetEventFailed_Event_DTC_0xe30055: start-on-event=GetEventFailed, operation=Event_DTC_0xe30055.GetEventFailed
        OpEventGetEventFailed_GetEventFailed_EvtInfo_DTC_0x600c49: start-on-event=GetEventFailed, operation=EvtInfo_DTC_0x600c49.GetEventFailed
        OpEventGetEventFailed_GetEventFailed_Event_DTC_0x600c49: start-on-event=GetEventFailed, operation=Event_DTC_0x600c49.GetEventFailed
        OpEventGetEventFailed_GetEventFailed_EvtInfo_DTC_0xc23b00: start-on-event=GetEventFailed, operation=EvtInfo_DTC_0xc23b00.GetEventFailed
        OpEventGetEventFailed_GetEventFailed_Event_DTC_0xc23b00: start-on-event=GetEventFailed, operation=Event_DTC_0xc23b00.GetEventFailed
        OpEventGetEventFailed_GetEventFailed_EvtInfo_DTC_0xc41600: start-on-event=GetEventFailed, operation=EvtInfo_DTC_0xc41600.GetEventFailed
        OpEventGetEventFailed_GetEventFailed_Event_DTC_0xc41600: start-on-event=GetEventFailed, operation=Event_DTC_0xc41600.GetEventFailed
        OpEventGetEventFailed_GetEventFailed_EvtInfo_DTC_0x9d234b: start-on-event=GetEventFailed, operation=EvtInfo_DTC_0x9d234b.GetEventFailed
        OpEventGetEventFailed_GetEventFailed_Event_DTC_0x9d234b: start-on-event=GetEventFailed, operation=Event_DTC_0x9d234b.GetEventFailed
        OpEventGetEventFailed_GetEventFailed_EvtInfo_DTC_0xc10200: start-on-event=GetEventFailed, operation=EvtInfo_DTC_0xc10200.GetEventFailed
        OpEventGetEventFailed_GetEventFailed_Event_DTC_0xc10200: start-on-event=GetEventFailed, operation=Event_DTC_0xc10200.GetEventFailed
        OpEventGetEventFailed_GetEventFailed_EvtInfo_DTC_0xc12100: start-on-event=GetEventFailed, operation=EvtInfo_DTC_0xc12100.GetEventFailed
        OpEventGetEventFailed_GetEventFailed_Event_DTC_0xc12100: start-on-event=GetEventFailed, operation=Event_DTC_0xc12100.GetEventFailed
        OpEventGetEventFailed_GetEventFailed_EvtInfo_DTC_0xc42800: start-on-event=GetEventFailed, operation=EvtInfo_DTC_0xc42800.GetEventFailed
        OpEventGetEventFailed_GetEventFailed_Event_DTC_0xc42800: start-on-event=GetEventFailed, operation=Event_DTC_0xc42800.GetEventFailed
        OpEventGetEventFailed_GetEventFailed_EvtInfo_DTC_0xc14000: start-on-event=GetEventFailed, operation=EvtInfo_DTC_0xc14000.GetEventFailed
        OpEventGetEventFailed_GetEventFailed_Event_DTC_0xc14000: start-on-event=GetEventFailed, operation=Event_DTC_0xc14000.GetEventFailed
        OpEventGetEventFailed_GetEventFailed_EvtInfo_DTC_0xc45a00: start-on-event=GetEventFailed, operation=EvtInfo_DTC_0xc45a00.GetEventFailed
        OpEventGetEventFailed_GetEventFailed_Event_DTC_0xc45a00: start-on-event=GetEventFailed, operation=Event_DTC_0xc45a00.GetEventFailed
        OpEventGetEventFailed_GetEventFailed_EvtInfo_DTC_0xc25300: start-on-event=GetEventFailed, operation=EvtInfo_DTC_0xc25300.GetEventFailed
        OpEventGetEventFailed_GetEventFailed_Event_DTC_0xc25300: start-on-event=GetEventFailed, operation=Event_DTC_0xc25300.GetEventFailed
        OpEventGetEventFailed_GetEventFailed_EvtInfo_DTC_0x600c62: start-on-event=GetEventFailed, operation=EvtInfo_DTC_0x600c62.GetEventFailed
        OpEventGetEventFailed_GetEventFailed_Event_DTC_0x600c62: start-on-event=GetEventFailed, operation=Event_DTC_0x600c62.GetEventFailed
        OpEventGetEventFailed_GetEventFailed_EvtInfo_DTC_0xc42200: start-on-event=GetEventFailed, operation=EvtInfo_DTC_0xc42200.GetEventFailed
        OpEventGetEventFailed_GetEventFailed_Event_DTC_0xc42200: start-on-event=GetEventFailed, operation=Event_DTC_0xc42200.GetEventFailed
        OpEventGetEventFailed_GetEventFailed_EvtInfo_DTC_0xc40300: start-on-event=GetEventFailed, operation=EvtInfo_DTC_0xc40300.GetEventFailed
        OpEventGetEventFailed_GetEventFailed_Event_DTC_0xc40300: start-on-event=GetEventFailed, operation=Event_DTC_0xc40300.GetEventFailed
        OpEventGetEventFailed_GetEventFailed_EvtInfo_DTC_0x600b49: start-on-event=GetEventFailed, operation=EvtInfo_DTC_0x600b49.GetEventFailed
        OpEventGetEventFailed_GetEventFailed_Event_DTC_0x600b49: start-on-event=GetEventFailed, operation=Event_DTC_0x600b49.GetEventFailed
        OpEventGetEventFailed_GetEventFailed_EvtInfo_DTC_0xc15900: start-on-event=GetEventFailed, operation=EvtInfo_DTC_0xc15900.GetEventFailed
        OpEventGetEventFailed_GetEventFailed_Event_DTC_0xc15900: start-on-event=GetEventFailed, operation=Event_DTC_0xc15900.GetEventFailed
        OpEventGetEventFailed_GetEventFailed_EvtInfo_DTC_0xc23a00: start-on-event=GetEventFailed, operation=EvtInfo_DTC_0xc23a00.GetEventFailed
        OpEventGetEventFailed_GetEventFailed_Event_DTC_0xc23a00: start-on-event=GetEventFailed, operation=Event_DTC_0xc23a00.GetEventFailed
        OpEventGetEventFailed_GetEventFailed_EvtInfo_DTC_0xc15500: start-on-event=GetEventFailed, operation=EvtInfo_DTC_0xc15500.GetEventFailed
        OpEventGetEventFailed_GetEventFailed_Event_DTC_0xc15500: start-on-event=GetEventFailed, operation=Event_DTC_0xc15500.GetEventFailed
        OpEventGetEventFailed_GetEventFailed_EvtInfo_DTC_0xc41500: start-on-event=GetEventFailed, operation=EvtInfo_DTC_0xc41500.GetEventFailed
        OpEventGetEventFailed_GetEventFailed_Event_DTC_0xc41500: start-on-event=GetEventFailed, operation=Event_DTC_0xc41500.GetEventFailed
        OpEventGetEventFailed_GetEventFailed_EvtInfo_DTC_0x5b0049: start-on-event=GetEventFailed, operation=EvtInfo_DTC_0x5b0049.GetEventFailed
        OpEventGetEventFailed_GetEventFailed_Event_DTC_0x5b0049: start-on-event=GetEventFailed, operation=Event_DTC_0x5b0049.GetEventFailed
        OpEventGetEventFailed_GetEventFailed_EvtInfo_DTC_0xf00317: start-on-event=GetEventFailed, operation=EvtInfo_DTC_0xf00317.GetEventFailed
        OpEventGetEventFailed_GetEventFailed_Event_DTC_0xf00317: start-on-event=GetEventFailed, operation=Event_DTC_0xf00317.GetEventFailed
        OpEventGetEventFailed_GetEventFailed_EvtInfo_DTC_0xf00316: start-on-event=GetEventFailed, operation=EvtInfo_DTC_0xf00316.GetEventFailed
        OpEventGetEventFailed_GetEventFailed_Event_DTC_0xf00316: start-on-event=GetEventFailed, operation=Event_DTC_0xf00316.GetEventFailed
        OpEventGetEventTested_GetEventTested_EvtInfo_DTC_0x600b62: start-on-event=GetEventTested, operation=EvtInfo_DTC_0x600b62.GetEventTested
        OpEventGetEventTested_GetEventTested_Event_DTC_0x600b62: start-on-event=GetEventTested, operation=Event_DTC_0x600b62.GetEventTested
        OpEventGetEventTested_GetEventTested_EvtInfo_DTC_0xc25600: start-on-event=GetEventTested, operation=EvtInfo_DTC_0xc25600.GetEventTested
        OpEventGetEventTested_GetEventTested_Event_DTC_0xc25600: start-on-event=GetEventTested, operation=Event_DTC_0xc25600.GetEventTested
        OpEventGetEventTested_GetEventTested_EvtInfo_DTC_0xf00049: start-on-event=GetEventTested, operation=EvtInfo_DTC_0xf00049.GetEventTested
        OpEventGetEventTested_GetEventTested_Event_DTC_0xf00049: start-on-event=GetEventTested, operation=Event_DTC_0xf00049.GetEventTested
        OpEventGetEventTested_GetEventTested_EvtInfo_DTC_0xe10000: start-on-event=GetEventTested, operation=EvtInfo_DTC_0xe10000.GetEventTested
        OpEventGetEventTested_GetEventTested_Event_DTC_0xe10000: start-on-event=GetEventTested, operation=Event_DTC_0xe10000.GetEventTested
        OpEventGetEventTested_GetEventTested_EvtInfo_DTC_0xf00168: start-on-event=GetEventTested, operation=EvtInfo_DTC_0xf00168.GetEventTested
        OpEventGetEventTested_GetEventTested_Event_DTC_0xf00168: start-on-event=GetEventTested, operation=Event_DTC_0xf00168.GetEventTested
        OpEventGetEventTested_GetEventTested_EvtInfo_DTC_0xf00042: start-on-event=GetEventTested, operation=EvtInfo_DTC_0xf00042.GetEventTested
        OpEventGetEventTested_GetEventTested_Event_DTC_0xf00042: start-on-event=GetEventTested, operation=Event_DTC_0xf00042.GetEventTested
        OpEventGetEventTested_GetEventTested_EvtInfo_DTC_0xc25200: start-on-event=GetEventTested, operation=EvtInfo_DTC_0xc25200.GetEventTested
        OpEventGetEventTested_GetEventTested_Event_DTC_0xc25200: start-on-event=GetEventTested, operation=Event_DTC_0xc25200.GetEventTested
        OpEventGetEventTested_GetEventTested_EvtInfo_DTC_0xe01492: start-on-event=GetEventTested, operation=EvtInfo_DTC_0xe01492.GetEventTested
        OpEventGetEventTested_GetEventTested_Event_DTC_0xe01492: start-on-event=GetEventTested, operation=Event_DTC_0xe01492.GetEventTested
        OpEventGetEventTested_GetEventTested_EvtInfo_DTC_0xc41522: start-on-event=GetEventTested, operation=EvtInfo_DTC_0xc41522.GetEventTested
        OpEventGetEventTested_GetEventTested_Event_DTC_0xc41522: start-on-event=GetEventTested, operation=Event_DTC_0xc41522.GetEventTested
        OpEventGetEventTested_GetEventTested_EvtInfo_DTC_0xc55700: start-on-event=GetEventTested, operation=EvtInfo_DTC_0xc55700.GetEventTested
        OpEventGetEventTested_GetEventTested_Event_DTC_0xc55700: start-on-event=GetEventTested, operation=Event_DTC_0xc55700.GetEventTested
        OpEventGetEventTested_GetEventTested_EvtInfo_DTC_0xc55300: start-on-event=GetEventTested, operation=EvtInfo_DTC_0xc55300.GetEventTested
        OpEventGetEventTested_GetEventTested_Event_DTC_0xc55300: start-on-event=GetEventTested, operation=Event_DTC_0xc55300.GetEventTested
        OpEventGetEventTested_GetEventTested_EvtInfo_DTC_0x5b0062: start-on-event=GetEventTested, operation=EvtInfo_DTC_0x5b0062.GetEventTested
        OpEventGetEventTested_GetEventTested_Event_DTC_0x5b0062: start-on-event=GetEventTested, operation=Event_DTC_0x5b0062.GetEventTested
        OpEventGetEventTested_GetEventTested_EvtInfo_DTC_0x511056: start-on-event=GetEventTested, operation=EvtInfo_DTC_0x511056.GetEventTested
        OpEventGetEventTested_GetEventTested_Event_DTC_0x511056: start-on-event=GetEventTested, operation=Event_DTC_0x511056.GetEventTested
        OpEventGetEventTested_GetEventTested_EvtInfo_DTC_0xc10000: start-on-event=GetEventTested, operation=EvtInfo_DTC_0xc10000.GetEventTested
        OpEventGetEventTested_GetEventTested_Event_DTC_0xc10000: start-on-event=GetEventTested, operation=Event_DTC_0xc10000.GetEventTested
        OpEventGetEventTested_GetEventTested_EvtInfo_DTC_0xe01481: start-on-event=GetEventTested, operation=EvtInfo_DTC_0xe01481.GetEventTested
        OpEventGetEventTested_GetEventTested_Event_DTC_0xe01481: start-on-event=GetEventTested, operation=Event_DTC_0xe01481.GetEventTested
        OpEventGetEventTested_GetEventTested_EvtInfo_DTC_0xc14600: start-on-event=GetEventTested, operation=EvtInfo_DTC_0xc14600.GetEventTested
        OpEventGetEventTested_GetEventTested_Event_DTC_0xc14600: start-on-event=GetEventTested, operation=Event_DTC_0xc14600.GetEventTested
        OpEventGetEventTested_GetEventTested_EvtInfo_DTC_0xe01647: start-on-event=GetEventTested, operation=EvtInfo_DTC_0xe01647.GetEventTested
        OpEventGetEventTested_GetEventTested_Event_DTC_0xe01647: start-on-event=GetEventTested, operation=Event_DTC_0xe01647.GetEventTested
        OpEventGetEventTested_GetEventTested_EvtInfo_DTC_0xe01648: start-on-event=GetEventTested, operation=EvtInfo_DTC_0xe01648.GetEventTested
        OpEventGetEventTested_GetEventTested_Event_DTC_0xe01648: start-on-event=GetEventTested, operation=Event_DTC_0xe01648.GetEventTested
        OpEventGetEventTested_GetEventTested_EvtInfo_DTC_0xc40100: start-on-event=GetEventTested, operation=EvtInfo_DTC_0xc40100.GetEventTested
        OpEventGetEventTested_GetEventTested_Event_DTC_0xc40100: start-on-event=GetEventTested, operation=Event_DTC_0xc40100.GetEventTested
        OpEventGetEventTested_GetEventTested_EvtInfo_DTC_0xc53b00: start-on-event=GetEventTested, operation=EvtInfo_DTC_0xc53b00.GetEventTested
        OpEventGetEventTested_GetEventTested_Event_DTC_0xc53b00: start-on-event=GetEventTested, operation=Event_DTC_0xc53b00.GetEventTested
        OpEventGetEventTested_GetEventTested_EvtInfo_DTC_0xf00061: start-on-event=GetEventTested, operation=EvtInfo_DTC_0xf00061.GetEventTested
        OpEventGetEventTested_GetEventTested_Event_DTC_0xf00061: start-on-event=GetEventTested, operation=Event_DTC_0xf00061.GetEventTested
        OpEventGetEventTested_GetEventTested_EvtInfo_DTC_0x600d49: start-on-event=GetEventTested, operation=EvtInfo_DTC_0x600d49.GetEventTested
        OpEventGetEventTested_GetEventTested_Event_DTC_0x600d49: start-on-event=GetEventTested, operation=Event_DTC_0x600d49.GetEventTested
        OpEventGetEventTested_GetEventTested_EvtInfo_DTC_0xc55400: start-on-event=GetEventTested, operation=EvtInfo_DTC_0xc55400.GetEventTested
        OpEventGetEventTested_GetEventTested_Event_DTC_0xc55400: start-on-event=GetEventTested, operation=Event_DTC_0xc55400.GetEventTested
        OpEventGetEventTested_GetEventTested_EvtInfo_DTC_0xe01478: start-on-event=GetEventTested, operation=EvtInfo_DTC_0xe01478.GetEventTested
        OpEventGetEventTested_GetEventTested_Event_DTC_0xe01478: start-on-event=GetEventTested, operation=Event_DTC_0xe01478.GetEventTested
        OpEventGetEventTested_GetEventTested_EvtInfo_DTC_0x502d00: start-on-event=GetEventTested, operation=EvtInfo_DTC_0x502d00.GetEventTested
        OpEventGetEventTested_GetEventTested_Event_DTC_0x502d00: start-on-event=GetEventTested, operation=Event_DTC_0x502d00.GetEventTested
        OpEventGetEventTested_GetEventTested_EvtInfo_DTC_0xc12200: start-on-event=GetEventTested, operation=EvtInfo_DTC_0xc12200.GetEventTested
        OpEventGetEventTested_GetEventTested_Event_DTC_0xc12200: start-on-event=GetEventTested, operation=Event_DTC_0xc12200.GetEventTested
        OpEventGetEventTested_GetEventTested_EvtInfo_DTC_0xc12600: start-on-event=GetEventTested, operation=EvtInfo_DTC_0xc12600.GetEventTested
        OpEventGetEventTested_GetEventTested_Event_DTC_0xc12600: start-on-event=GetEventTested, operation=Event_DTC_0xc12600.GetEventTested
        OpEventGetEventTested_GetEventTested_EvtInfo_DTC_0xf00368: start-on-event=GetEventTested, operation=EvtInfo_DTC_0xf00368.GetEventTested
        OpEventGetEventTested_GetEventTested_Event_DTC_0xf00368: start-on-event=GetEventTested, operation=Event_DTC_0xf00368.GetEventTested
        OpEventGetEventTested_GetEventTested_EvtInfo_DTC_0x600d62: start-on-event=GetEventTested, operation=EvtInfo_DTC_0x600d62.GetEventTested
        OpEventGetEventTested_GetEventTested_Event_DTC_0x600d62: start-on-event=GetEventTested, operation=Event_DTC_0x600d62.GetEventTested
        OpEventGetEventTested_GetEventTested_EvtInfo_DTC_0xc42300: start-on-event=GetEventTested, operation=EvtInfo_DTC_0xc42300.GetEventTested
        OpEventGetEventTested_GetEventTested_Event_DTC_0xc42300: start-on-event=GetEventTested, operation=Event_DTC_0xc42300.GetEventTested
        OpEventGetEventTested_GetEventTested_EvtInfo_DTC_0xc53c00: start-on-event=GetEventTested, operation=EvtInfo_DTC_0xc53c00.GetEventTested
        OpEventGetEventTested_GetEventTested_Event_DTC_0xc53c00: start-on-event=GetEventTested, operation=Event_DTC_0xc53c00.GetEventTested
        OpEventGetEventTested_GetEventTested_EvtInfo_DTC_0xe30055: start-on-event=GetEventTested, operation=EvtInfo_DTC_0xe30055.GetEventTested
        OpEventGetEventTested_GetEventTested_Event_DTC_0xe30055: start-on-event=GetEventTested, operation=Event_DTC_0xe30055.GetEventTested
        OpEventGetEventTested_GetEventTested_EvtInfo_DTC_0x600c49: start-on-event=GetEventTested, operation=EvtInfo_DTC_0x600c49.GetEventTested
        OpEventGetEventTested_GetEventTested_Event_DTC_0x600c49: start-on-event=GetEventTested, operation=Event_DTC_0x600c49.GetEventTested
        OpEventGetEventTested_GetEventTested_EvtInfo_DTC_0xc23b00: start-on-event=GetEventTested, operation=EvtInfo_DTC_0xc23b00.GetEventTested
        OpEventGetEventTested_GetEventTested_Event_DTC_0xc23b00: start-on-event=GetEventTested, operation=Event_DTC_0xc23b00.GetEventTested
        OpEventGetEventTested_GetEventTested_EvtInfo_DTC_0xc41600: start-on-event=GetEventTested, operation=EvtInfo_DTC_0xc41600.GetEventTested
        OpEventGetEventTested_GetEventTested_Event_DTC_0xc41600: start-on-event=GetEventTested, operation=Event_DTC_0xc41600.GetEventTested
        OpEventGetEventTested_GetEventTested_EvtInfo_DTC_0x9d234b: start-on-event=GetEventTested, operation=EvtInfo_DTC_0x9d234b.GetEventTested
        OpEventGetEventTested_GetEventTested_Event_DTC_0x9d234b: start-on-event=GetEventTested, operation=Event_DTC_0x9d234b.GetEventTested
        OpEventGetEventTested_GetEventTested_EvtInfo_DTC_0xc10200: start-on-event=GetEventTested, operation=EvtInfo_DTC_0xc10200.GetEventTested
        OpEventGetEventTested_GetEventTested_Event_DTC_0xc10200: start-on-event=GetEventTested, operation=Event_DTC_0xc10200.GetEventTested
        OpEventGetEventTested_GetEventTested_EvtInfo_DTC_0xc12100: start-on-event=GetEventTested, operation=EvtInfo_DTC_0xc12100.GetEventTested
        OpEventGetEventTested_GetEventTested_Event_DTC_0xc12100: start-on-event=GetEventTested, operation=Event_DTC_0xc12100.GetEventTested
        OpEventGetEventTested_GetEventTested_EvtInfo_DTC_0xc42800: start-on-event=GetEventTested, operation=EvtInfo_DTC_0xc42800.GetEventTested
        OpEventGetEventTested_GetEventTested_Event_DTC_0xc42800: start-on-event=GetEventTested, operation=Event_DTC_0xc42800.GetEventTested
        OpEventGetEventTested_GetEventTested_EvtInfo_DTC_0xc14000: start-on-event=GetEventTested, operation=EvtInfo_DTC_0xc14000.GetEventTested
        OpEventGetEventTested_GetEventTested_Event_DTC_0xc14000: start-on-event=GetEventTested, operation=Event_DTC_0xc14000.GetEventTested
        OpEventGetEventTested_GetEventTested_EvtInfo_DTC_0xc45a00: start-on-event=GetEventTested, operation=EvtInfo_DTC_0xc45a00.GetEventTested
        OpEventGetEventTested_GetEventTested_Event_DTC_0xc45a00: start-on-event=GetEventTested, operation=Event_DTC_0xc45a00.GetEventTested
        OpEventGetEventTested_GetEventTested_EvtInfo_DTC_0xc25300: start-on-event=GetEventTested, operation=EvtInfo_DTC_0xc25300.GetEventTested
        OpEventGetEventTested_GetEventTested_Event_DTC_0xc25300: start-on-event=GetEventTested, operation=Event_DTC_0xc25300.GetEventTested
        OpEventGetEventTested_GetEventTested_EvtInfo_DTC_0x600c62: start-on-event=GetEventTested, operation=EvtInfo_DTC_0x600c62.GetEventTested
        OpEventGetEventTested_GetEventTested_Event_DTC_0x600c62: start-on-event=GetEventTested, operation=Event_DTC_0x600c62.GetEventTested
        OpEventGetEventTested_GetEventTested_EvtInfo_DTC_0xc42200: start-on-event=GetEventTested, operation=EvtInfo_DTC_0xc42200.GetEventTested
        OpEventGetEventTested_GetEventTested_Event_DTC_0xc42200: start-on-event=GetEventTested, operation=Event_DTC_0xc42200.GetEventTested
        OpEventGetEventTested_GetEventTested_EvtInfo_DTC_0xc40300: start-on-event=GetEventTested, operation=EvtInfo_DTC_0xc40300.GetEventTested
        OpEventGetEventTested_GetEventTested_Event_DTC_0xc40300: start-on-event=GetEventTested, operation=Event_DTC_0xc40300.GetEventTested
        OpEventGetEventTested_GetEventTested_EvtInfo_DTC_0x600b49: start-on-event=GetEventTested, operation=EvtInfo_DTC_0x600b49.GetEventTested
        OpEventGetEventTested_GetEventTested_Event_DTC_0x600b49: start-on-event=GetEventTested, operation=Event_DTC_0x600b49.GetEventTested
        OpEventGetEventTested_GetEventTested_EvtInfo_DTC_0xc15900: start-on-event=GetEventTested, operation=EvtInfo_DTC_0xc15900.GetEventTested
        OpEventGetEventTested_GetEventTested_Event_DTC_0xc15900: start-on-event=GetEventTested, operation=Event_DTC_0xc15900.GetEventTested
        OpEventGetEventTested_GetEventTested_EvtInfo_DTC_0xc23a00: start-on-event=GetEventTested, operation=EvtInfo_DTC_0xc23a00.GetEventTested
        OpEventGetEventTested_GetEventTested_Event_DTC_0xc23a00: start-on-event=GetEventTested, operation=Event_DTC_0xc23a00.GetEventTested
        OpEventGetEventTested_GetEventTested_EvtInfo_DTC_0xc15500: start-on-event=GetEventTested, operation=EvtInfo_DTC_0xc15500.GetEventTested
        OpEventGetEventTested_GetEventTested_Event_DTC_0xc15500: start-on-event=GetEventTested, operation=Event_DTC_0xc15500.GetEventTested
        OpEventGetEventTested_GetEventTested_EvtInfo_DTC_0xc41500: start-on-event=GetEventTested, operation=EvtInfo_DTC_0xc41500.GetEventTested
        OpEventGetEventTested_GetEventTested_Event_DTC_0xc41500: start-on-event=GetEventTested, operation=Event_DTC_0xc41500.GetEventTested
        OpEventGetEventTested_GetEventTested_EvtInfo_DTC_0x5b0049: start-on-event=GetEventTested, operation=EvtInfo_DTC_0x5b0049.GetEventTested
        OpEventGetEventTested_GetEventTested_Event_DTC_0x5b0049: start-on-event=GetEventTested, operation=Event_DTC_0x5b0049.GetEventTested
        OpEventGetEventTested_GetEventTested_EvtInfo_DTC_0xf00317: start-on-event=GetEventTested, operation=EvtInfo_DTC_0xf00317.GetEventTested
        OpEventGetEventTested_GetEventTested_Event_DTC_0xf00317: start-on-event=GetEventTested, operation=Event_DTC_0xf00317.GetEventTested
        OpEventGetEventTested_GetEventTested_EvtInfo_DTC_0xf00316: start-on-event=GetEventTested, operation=EvtInfo_DTC_0xf00316.GetEventTested
        OpEventGetEventTested_GetEventTested_Event_DTC_0xf00316: start-on-event=GetEventTested, operation=Event_DTC_0xf00316.GetEventTested
        OpEventGetDTCOfEvent_GetDTCOfEvent_EvtInfo_DTC_0x600b62: start-on-event=GetDTCOfEvent, operation=EvtInfo_DTC_0x600b62.GetDTCOfEvent
        OpEventGetDTCOfEvent_GetDTCOfEvent_Event_DTC_0x600b62: start-on-event=GetDTCOfEvent, operation=Event_DTC_0x600b62.GetDTCOfEvent
        OpEventGetDTCOfEvent_GetDTCOfEvent_EvtInfo_DTC_0xc25600: start-on-event=GetDTCOfEvent, operation=EvtInfo_DTC_0xc25600.GetDTCOfEvent
        OpEventGetDTCOfEvent_GetDTCOfEvent_Event_DTC_0xc25600: start-on-event=GetDTCOfEvent, operation=Event_DTC_0xc25600.GetDTCOfEvent
        OpEventGetDTCOfEvent_GetDTCOfEvent_EvtInfo_DTC_0xf00049: start-on-event=GetDTCOfEvent, operation=EvtInfo_DTC_0xf00049.GetDTCOfEvent
        OpEventGetDTCOfEvent_GetDTCOfEvent_Event_DTC_0xf00049: start-on-event=GetDTCOfEvent, operation=Event_DTC_0xf00049.GetDTCOfEvent
        OpEventGetDTCOfEvent_GetDTCOfEvent_EvtInfo_DTC_0xe10000: start-on-event=GetDTCOfEvent, operation=EvtInfo_DTC_0xe10000.GetDTCOfEvent
        OpEventGetDTCOfEvent_GetDTCOfEvent_Event_DTC_0xe10000: start-on-event=GetDTCOfEvent, operation=Event_DTC_0xe10000.GetDTCOfEvent
        OpEventGetDTCOfEvent_GetDTCOfEvent_EvtInfo_DTC_0xf00168: start-on-event=GetDTCOfEvent, operation=EvtInfo_DTC_0xf00168.GetDTCOfEvent
        OpEventGetDTCOfEvent_GetDTCOfEvent_Event_DTC_0xf00168: start-on-event=GetDTCOfEvent, operation=Event_DTC_0xf00168.GetDTCOfEvent
        OpEventGetDTCOfEvent_GetDTCOfEvent_EvtInfo_DTC_0xf00042: start-on-event=GetDTCOfEvent, operation=EvtInfo_DTC_0xf00042.GetDTCOfEvent
        OpEventGetDTCOfEvent_GetDTCOfEvent_Event_DTC_0xf00042: start-on-event=GetDTCOfEvent, operation=Event_DTC_0xf00042.GetDTCOfEvent
        OpEventGetDTCOfEvent_GetDTCOfEvent_EvtInfo_DTC_0xc25200: start-on-event=GetDTCOfEvent, operation=EvtInfo_DTC_0xc25200.GetDTCOfEvent
        OpEventGetDTCOfEvent_GetDTCOfEvent_Event_DTC_0xc25200: start-on-event=GetDTCOfEvent, operation=Event_DTC_0xc25200.GetDTCOfEvent
        OpEventGetDTCOfEvent_GetDTCOfEvent_EvtInfo_DTC_0xe01492: start-on-event=GetDTCOfEvent, operation=EvtInfo_DTC_0xe01492.GetDTCOfEvent
        OpEventGetDTCOfEvent_GetDTCOfEvent_Event_DTC_0xe01492: start-on-event=GetDTCOfEvent, operation=Event_DTC_0xe01492.GetDTCOfEvent
        OpEventGetDTCOfEvent_GetDTCOfEvent_EvtInfo_DTC_0xc41522: start-on-event=GetDTCOfEvent, operation=EvtInfo_DTC_0xc41522.GetDTCOfEvent
        OpEventGetDTCOfEvent_GetDTCOfEvent_Event_DTC_0xc41522: start-on-event=GetDTCOfEvent, operation=Event_DTC_0xc41522.GetDTCOfEvent
        OpEventGetDTCOfEvent_GetDTCOfEvent_EvtInfo_DTC_0xc55700: start-on-event=GetDTCOfEvent, operation=EvtInfo_DTC_0xc55700.GetDTCOfEvent
        OpEventGetDTCOfEvent_GetDTCOfEvent_Event_DTC_0xc55700: start-on-event=GetDTCOfEvent, operation=Event_DTC_0xc55700.GetDTCOfEvent
        OpEventGetDTCOfEvent_GetDTCOfEvent_EvtInfo_DTC_0xc55300: start-on-event=GetDTCOfEvent, operation=EvtInfo_DTC_0xc55300.GetDTCOfEvent
        OpEventGetDTCOfEvent_GetDTCOfEvent_Event_DTC_0xc55300: start-on-event=GetDTCOfEvent, operation=Event_DTC_0xc55300.GetDTCOfEvent
        OpEventGetDTCOfEvent_GetDTCOfEvent_EvtInfo_DTC_0x5b0062: start-on-event=GetDTCOfEvent, operation=EvtInfo_DTC_0x5b0062.GetDTCOfEvent
        OpEventGetDTCOfEvent_GetDTCOfEvent_Event_DTC_0x5b0062: start-on-event=GetDTCOfEvent, operation=Event_DTC_0x5b0062.GetDTCOfEvent
        OpEventGetDTCOfEvent_GetDTCOfEvent_EvtInfo_DTC_0x511056: start-on-event=GetDTCOfEvent, operation=EvtInfo_DTC_0x511056.GetDTCOfEvent
        OpEventGetDTCOfEvent_GetDTCOfEvent_Event_DTC_0x511056: start-on-event=GetDTCOfEvent, operation=Event_DTC_0x511056.GetDTCOfEvent
        OpEventGetDTCOfEvent_GetDTCOfEvent_EvtInfo_DTC_0xc10000: start-on-event=GetDTCOfEvent, operation=EvtInfo_DTC_0xc10000.GetDTCOfEvent
        OpEventGetDTCOfEvent_GetDTCOfEvent_Event_DTC_0xc10000: start-on-event=GetDTCOfEvent, operation=Event_DTC_0xc10000.GetDTCOfEvent
        OpEventGetDTCOfEvent_GetDTCOfEvent_EvtInfo_DTC_0xe01481: start-on-event=GetDTCOfEvent, operation=EvtInfo_DTC_0xe01481.GetDTCOfEvent
        OpEventGetDTCOfEvent_GetDTCOfEvent_Event_DTC_0xe01481: start-on-event=GetDTCOfEvent, operation=Event_DTC_0xe01481.GetDTCOfEvent
        OpEventGetDTCOfEvent_GetDTCOfEvent_EvtInfo_DTC_0xc14600: start-on-event=GetDTCOfEvent, operation=EvtInfo_DTC_0xc14600.GetDTCOfEvent
        OpEventGetDTCOfEvent_GetDTCOfEvent_Event_DTC_0xc14600: start-on-event=GetDTCOfEvent, operation=Event_DTC_0xc14600.GetDTCOfEvent
        OpEventGetDTCOfEvent_GetDTCOfEvent_EvtInfo_DTC_0xe01647: start-on-event=GetDTCOfEvent, operation=EvtInfo_DTC_0xe01647.GetDTCOfEvent
        OpEventGetDTCOfEvent_GetDTCOfEvent_Event_DTC_0xe01647: start-on-event=GetDTCOfEvent, operation=Event_DTC_0xe01647.GetDTCOfEvent
        OpEventGetDTCOfEvent_GetDTCOfEvent_EvtInfo_DTC_0xe01648: start-on-event=GetDTCOfEvent, operation=EvtInfo_DTC_0xe01648.GetDTCOfEvent
        OpEventGetDTCOfEvent_GetDTCOfEvent_Event_DTC_0xe01648: start-on-event=GetDTCOfEvent, operation=Event_DTC_0xe01648.GetDTCOfEvent
        OpEventGetDTCOfEvent_GetDTCOfEvent_EvtInfo_DTC_0xc40100: start-on-event=GetDTCOfEvent, operation=EvtInfo_DTC_0xc40100.GetDTCOfEvent
        OpEventGetDTCOfEvent_GetDTCOfEvent_Event_DTC_0xc40100: start-on-event=GetDTCOfEvent, operation=Event_DTC_0xc40100.GetDTCOfEvent
        OpEventGetDTCOfEvent_GetDTCOfEvent_EvtInfo_DTC_0xc53b00: start-on-event=GetDTCOfEvent, operation=EvtInfo_DTC_0xc53b00.GetDTCOfEvent
        OpEventGetDTCOfEvent_GetDTCOfEvent_Event_DTC_0xc53b00: start-on-event=GetDTCOfEvent, operation=Event_DTC_0xc53b00.GetDTCOfEvent
        OpEventGetDTCOfEvent_GetDTCOfEvent_EvtInfo_DTC_0xf00061: start-on-event=GetDTCOfEvent, operation=EvtInfo_DTC_0xf00061.GetDTCOfEvent
        OpEventGetDTCOfEvent_GetDTCOfEvent_Event_DTC_0xf00061: start-on-event=GetDTCOfEvent, operation=Event_DTC_0xf00061.GetDTCOfEvent
        OpEventGetDTCOfEvent_GetDTCOfEvent_EvtInfo_DTC_0x600d49: start-on-event=GetDTCOfEvent, operation=EvtInfo_DTC_0x600d49.GetDTCOfEvent
        OpEventGetDTCOfEvent_GetDTCOfEvent_Event_DTC_0x600d49: start-on-event=GetDTCOfEvent, operation=Event_DTC_0x600d49.GetDTCOfEvent
        OpEventGetDTCOfEvent_GetDTCOfEvent_EvtInfo_DTC_0xc55400: start-on-event=GetDTCOfEvent, operation=EvtInfo_DTC_0xc55400.GetDTCOfEvent
        OpEventGetDTCOfEvent_GetDTCOfEvent_Event_DTC_0xc55400: start-on-event=GetDTCOfEvent, operation=Event_DTC_0xc55400.GetDTCOfEvent
        OpEventGetDTCOfEvent_GetDTCOfEvent_EvtInfo_DTC_0xe01478: start-on-event=GetDTCOfEvent, operation=EvtInfo_DTC_0xe01478.GetDTCOfEvent
        OpEventGetDTCOfEvent_GetDTCOfEvent_Event_DTC_0xe01478: start-on-event=GetDTCOfEvent, operation=Event_DTC_0xe01478.GetDTCOfEvent
        OpEventGetDTCOfEvent_GetDTCOfEvent_EvtInfo_DTC_0x502d00: start-on-event=GetDTCOfEvent, operation=EvtInfo_DTC_0x502d00.GetDTCOfEvent
        OpEventGetDTCOfEvent_GetDTCOfEvent_Event_DTC_0x502d00: start-on-event=GetDTCOfEvent, operation=Event_DTC_0x502d00.GetDTCOfEvent
        OpEventGetDTCOfEvent_GetDTCOfEvent_EvtInfo_DTC_0xc12200: start-on-event=GetDTCOfEvent, operation=EvtInfo_DTC_0xc12200.GetDTCOfEvent
        OpEventGetDTCOfEvent_GetDTCOfEvent_Event_DTC_0xc12200: start-on-event=GetDTCOfEvent, operation=Event_DTC_0xc12200.GetDTCOfEvent
        OpEventGetDTCOfEvent_GetDTCOfEvent_EvtInfo_DTC_0xc12600: start-on-event=GetDTCOfEvent, operation=EvtInfo_DTC_0xc12600.GetDTCOfEvent
        OpEventGetDTCOfEvent_GetDTCOfEvent_Event_DTC_0xc12600: start-on-event=GetDTCOfEvent, operation=Event_DTC_0xc12600.GetDTCOfEvent
        OpEventGetDTCOfEvent_GetDTCOfEvent_EvtInfo_DTC_0xf00368: start-on-event=GetDTCOfEvent, operation=EvtInfo_DTC_0xf00368.GetDTCOfEvent
        OpEventGetDTCOfEvent_GetDTCOfEvent_Event_DTC_0xf00368: start-on-event=GetDTCOfEvent, operation=Event_DTC_0xf00368.GetDTCOfEvent
        OpEventGetDTCOfEvent_GetDTCOfEvent_EvtInfo_DTC_0x600d62: start-on-event=GetDTCOfEvent, operation=EvtInfo_DTC_0x600d62.GetDTCOfEvent
        OpEventGetDTCOfEvent_GetDTCOfEvent_Event_DTC_0x600d62: start-on-event=GetDTCOfEvent, operation=Event_DTC_0x600d62.GetDTCOfEvent
        OpEventGetDTCOfEvent_GetDTCOfEvent_EvtInfo_DTC_0xc42300: start-on-event=GetDTCOfEvent, operation=EvtInfo_DTC_0xc42300.GetDTCOfEvent
        OpEventGetDTCOfEvent_GetDTCOfEvent_Event_DTC_0xc42300: start-on-event=GetDTCOfEvent, operation=Event_DTC_0xc42300.GetDTCOfEvent
        OpEventGetDTCOfEvent_GetDTCOfEvent_EvtInfo_DTC_0xc53c00: start-on-event=GetDTCOfEvent, operation=EvtInfo_DTC_0xc53c00.GetDTCOfEvent
        OpEventGetDTCOfEvent_GetDTCOfEvent_Event_DTC_0xc53c00: start-on-event=GetDTCOfEvent, operation=Event_DTC_0xc53c00.GetDTCOfEvent
        OpEventGetDTCOfEvent_GetDTCOfEvent_EvtInfo_DTC_0xe30055: start-on-event=GetDTCOfEvent, operation=EvtInfo_DTC_0xe30055.GetDTCOfEvent
        OpEventGetDTCOfEvent_GetDTCOfEvent_Event_DTC_0xe30055: start-on-event=GetDTCOfEvent, operation=Event_DTC_0xe30055.GetDTCOfEvent
        OpEventGetDTCOfEvent_GetDTCOfEvent_EvtInfo_DTC_0x600c49: start-on-event=GetDTCOfEvent, operation=EvtInfo_DTC_0x600c49.GetDTCOfEvent
        OpEventGetDTCOfEvent_GetDTCOfEvent_Event_DTC_0x600c49: start-on-event=GetDTCOfEvent, operation=Event_DTC_0x600c49.GetDTCOfEvent
        OpEventGetDTCOfEvent_GetDTCOfEvent_EvtInfo_DTC_0xc23b00: start-on-event=GetDTCOfEvent, operation=EvtInfo_DTC_0xc23b00.GetDTCOfEvent
        OpEventGetDTCOfEvent_GetDTCOfEvent_Event_DTC_0xc23b00: start-on-event=GetDTCOfEvent, operation=Event_DTC_0xc23b00.GetDTCOfEvent
        OpEventGetDTCOfEvent_GetDTCOfEvent_EvtInfo_DTC_0xc41600: start-on-event=GetDTCOfEvent, operation=EvtInfo_DTC_0xc41600.GetDTCOfEvent
        OpEventGetDTCOfEvent_GetDTCOfEvent_Event_DTC_0xc41600: start-on-event=GetDTCOfEvent, operation=Event_DTC_0xc41600.GetDTCOfEvent
        OpEventGetDTCOfEvent_GetDTCOfEvent_EvtInfo_DTC_0x9d234b: start-on-event=GetDTCOfEvent, operation=EvtInfo_DTC_0x9d234b.GetDTCOfEvent
        OpEventGetDTCOfEvent_GetDTCOfEvent_Event_DTC_0x9d234b: start-on-event=GetDTCOfEvent, operation=Event_DTC_0x9d234b.GetDTCOfEvent
        OpEventGetDTCOfEvent_GetDTCOfEvent_EvtInfo_DTC_0xc10200: start-on-event=GetDTCOfEvent, operation=EvtInfo_DTC_0xc10200.GetDTCOfEvent
        OpEventGetDTCOfEvent_GetDTCOfEvent_Event_DTC_0xc10200: start-on-event=GetDTCOfEvent, operation=Event_DTC_0xc10200.GetDTCOfEvent
        OpEventGetDTCOfEvent_GetDTCOfEvent_EvtInfo_DTC_0xc12100: start-on-event=GetDTCOfEvent, operation=EvtInfo_DTC_0xc12100.GetDTCOfEvent
        OpEventGetDTCOfEvent_GetDTCOfEvent_Event_DTC_0xc12100: start-on-event=GetDTCOfEvent, operation=Event_DTC_0xc12100.GetDTCOfEvent
        OpEventGetDTCOfEvent_GetDTCOfEvent_EvtInfo_DTC_0xc42800: start-on-event=GetDTCOfEvent, operation=EvtInfo_DTC_0xc42800.GetDTCOfEvent
        OpEventGetDTCOfEvent_GetDTCOfEvent_Event_DTC_0xc42800: start-on-event=GetDTCOfEvent, operation=Event_DTC_0xc42800.GetDTCOfEvent
        OpEventGetDTCOfEvent_GetDTCOfEvent_EvtInfo_DTC_0xc14000: start-on-event=GetDTCOfEvent, operation=EvtInfo_DTC_0xc14000.GetDTCOfEvent
        OpEventGetDTCOfEvent_GetDTCOfEvent_Event_DTC_0xc14000: start-on-event=GetDTCOfEvent, operation=Event_DTC_0xc14000.GetDTCOfEvent
        OpEventGetDTCOfEvent_GetDTCOfEvent_EvtInfo_DTC_0xc45a00: start-on-event=GetDTCOfEvent, operation=EvtInfo_DTC_0xc45a00.GetDTCOfEvent
        OpEventGetDTCOfEvent_GetDTCOfEvent_Event_DTC_0xc45a00: start-on-event=GetDTCOfEvent, operation=Event_DTC_0xc45a00.GetDTCOfEvent
        OpEventGetDTCOfEvent_GetDTCOfEvent_EvtInfo_DTC_0xc25300: start-on-event=GetDTCOfEvent, operation=EvtInfo_DTC_0xc25300.GetDTCOfEvent
        OpEventGetDTCOfEvent_GetDTCOfEvent_Event_DTC_0xc25300: start-on-event=GetDTCOfEvent, operation=Event_DTC_0xc25300.GetDTCOfEvent
        OpEventGetDTCOfEvent_GetDTCOfEvent_EvtInfo_DTC_0x600c62: start-on-event=GetDTCOfEvent, operation=EvtInfo_DTC_0x600c62.GetDTCOfEvent
        OpEventGetDTCOfEvent_GetDTCOfEvent_Event_DTC_0x600c62: start-on-event=GetDTCOfEvent, operation=Event_DTC_0x600c62.GetDTCOfEvent
        OpEventGetDTCOfEvent_GetDTCOfEvent_EvtInfo_DTC_0xc42200: start-on-event=GetDTCOfEvent, operation=EvtInfo_DTC_0xc42200.GetDTCOfEvent
        OpEventGetDTCOfEvent_GetDTCOfEvent_Event_DTC_0xc42200: start-on-event=GetDTCOfEvent, operation=Event_DTC_0xc42200.GetDTCOfEvent
        OpEventGetDTCOfEvent_GetDTCOfEvent_EvtInfo_DTC_0xc40300: start-on-event=GetDTCOfEvent, operation=EvtInfo_DTC_0xc40300.GetDTCOfEvent
        OpEventGetDTCOfEvent_GetDTCOfEvent_Event_DTC_0xc40300: start-on-event=GetDTCOfEvent, operation=Event_DTC_0xc40300.GetDTCOfEvent
        OpEventGetDTCOfEvent_GetDTCOfEvent_EvtInfo_DTC_0x600b49: start-on-event=GetDTCOfEvent, operation=EvtInfo_DTC_0x600b49.GetDTCOfEvent
        OpEventGetDTCOfEvent_GetDTCOfEvent_Event_DTC_0x600b49: start-on-event=GetDTCOfEvent, operation=Event_DTC_0x600b49.GetDTCOfEvent
        OpEventGetDTCOfEvent_GetDTCOfEvent_EvtInfo_DTC_0xc15900: start-on-event=GetDTCOfEvent, operation=EvtInfo_DTC_0xc15900.GetDTCOfEvent
        OpEventGetDTCOfEvent_GetDTCOfEvent_Event_DTC_0xc15900: start-on-event=GetDTCOfEvent, operation=Event_DTC_0xc15900.GetDTCOfEvent
        OpEventGetDTCOfEvent_GetDTCOfEvent_EvtInfo_DTC_0xc23a00: start-on-event=GetDTCOfEvent, operation=EvtInfo_DTC_0xc23a00.GetDTCOfEvent
        OpEventGetDTCOfEvent_GetDTCOfEvent_Event_DTC_0xc23a00: start-on-event=GetDTCOfEvent, operation=Event_DTC_0xc23a00.GetDTCOfEvent
        OpEventGetDTCOfEvent_GetDTCOfEvent_EvtInfo_DTC_0xc15500: start-on-event=GetDTCOfEvent, operation=EvtInfo_DTC_0xc15500.GetDTCOfEvent
        OpEventGetDTCOfEvent_GetDTCOfEvent_Event_DTC_0xc15500: start-on-event=GetDTCOfEvent, operation=Event_DTC_0xc15500.GetDTCOfEvent
        OpEventGetDTCOfEvent_GetDTCOfEvent_EvtInfo_DTC_0xc41500: start-on-event=GetDTCOfEvent, operation=EvtInfo_DTC_0xc41500.GetDTCOfEvent
        OpEventGetDTCOfEvent_GetDTCOfEvent_Event_DTC_0xc41500: start-on-event=GetDTCOfEvent, operation=Event_DTC_0xc41500.GetDTCOfEvent
        OpEventGetDTCOfEvent_GetDTCOfEvent_EvtInfo_DTC_0x5b0049: start-on-event=GetDTCOfEvent, operation=EvtInfo_DTC_0x5b0049.GetDTCOfEvent
        OpEventGetDTCOfEvent_GetDTCOfEvent_Event_DTC_0x5b0049: start-on-event=GetDTCOfEvent, operation=Event_DTC_0x5b0049.GetDTCOfEvent
        OpEventGetDTCOfEvent_GetDTCOfEvent_EvtInfo_DTC_0xf00317: start-on-event=GetDTCOfEvent, operation=EvtInfo_DTC_0xf00317.GetDTCOfEvent
        OpEventGetDTCOfEvent_GetDTCOfEvent_Event_DTC_0xf00317: start-on-event=GetDTCOfEvent, operation=Event_DTC_0xf00317.GetDTCOfEvent
        OpEventGetDTCOfEvent_GetDTCOfEvent_EvtInfo_DTC_0xf00316: start-on-event=GetDTCOfEvent, operation=EvtInfo_DTC_0xf00316.GetDTCOfEvent
        OpEventGetDTCOfEvent_GetDTCOfEvent_Event_DTC_0xf00316: start-on-event=GetDTCOfEvent, operation=Event_DTC_0xf00316.GetDTCOfEvent
        OpEventGetFaultDetectionCounter_GetFaultDetectionCounter_EvtInfo_DTC_0x600b62: start-on-event=GetFaultDetectionCounter, operation=EvtInfo_DTC_0x600b62.GetFaultDetectionCounter
        OpEventGetFaultDetectionCounter_GetFaultDetectionCounter_Event_DTC_0x600b62: start-on-event=GetFaultDetectionCounter, operation=Event_DTC_0x600b62.GetFaultDetectionCounter
        OpEventGetFaultDetectionCounter_GetFaultDetectionCounter_EvtInfo_DTC_0xc25600: start-on-event=GetFaultDetectionCounter, operation=EvtInfo_DTC_0xc25600.GetFaultDetectionCounter
        OpEventGetFaultDetectionCounter_GetFaultDetectionCounter_Event_DTC_0xc25600: start-on-event=GetFaultDetectionCounter, operation=Event_DTC_0xc25600.GetFaultDetectionCounter
        OpEventGetFaultDetectionCounter_GetFaultDetectionCounter_EvtInfo_DTC_0xf00049: start-on-event=GetFaultDetectionCounter, operation=EvtInfo_DTC_0xf00049.GetFaultDetectionCounter
        OpEventGetFaultDetectionCounter_GetFaultDetectionCounter_Event_DTC_0xf00049: start-on-event=GetFaultDetectionCounter, operation=Event_DTC_0xf00049.GetFaultDetectionCounter
        OpEventGetFaultDetectionCounter_GetFaultDetectionCounter_EvtInfo_DTC_0xe10000: start-on-event=GetFaultDetectionCounter, operation=EvtInfo_DTC_0xe10000.GetFaultDetectionCounter
        OpEventGetFaultDetectionCounter_GetFaultDetectionCounter_Event_DTC_0xe10000: start-on-event=GetFaultDetectionCounter, operation=Event_DTC_0xe10000.GetFaultDetectionCounter
        OpEventGetFaultDetectionCounter_GetFaultDetectionCounter_EvtInfo_DTC_0xf00168: start-on-event=GetFaultDetectionCounter, operation=EvtInfo_DTC_0xf00168.GetFaultDetectionCounter
        OpEventGetFaultDetectionCounter_GetFaultDetectionCounter_Event_DTC_0xf00168: start-on-event=GetFaultDetectionCounter, operation=Event_DTC_0xf00168.GetFaultDetectionCounter
        OpEventGetFaultDetectionCounter_GetFaultDetectionCounter_EvtInfo_DTC_0xf00042: start-on-event=GetFaultDetectionCounter, operation=EvtInfo_DTC_0xf00042.GetFaultDetectionCounter
        OpEventGetFaultDetectionCounter_GetFaultDetectionCounter_Event_DTC_0xf00042: start-on-event=GetFaultDetectionCounter, operation=Event_DTC_0xf00042.GetFaultDetectionCounter
        OpEventGetFaultDetectionCounter_GetFaultDetectionCounter_EvtInfo_DTC_0xc25200: start-on-event=GetFaultDetectionCounter, operation=EvtInfo_DTC_0xc25200.GetFaultDetectionCounter
        OpEventGetFaultDetectionCounter_GetFaultDetectionCounter_Event_DTC_0xc25200: start-on-event=GetFaultDetectionCounter, operation=Event_DTC_0xc25200.GetFaultDetectionCounter
        OpEventGetFaultDetectionCounter_GetFaultDetectionCounter_EvtInfo_DTC_0xe01492: start-on-event=GetFaultDetectionCounter, operation=EvtInfo_DTC_0xe01492.GetFaultDetectionCounter
        OpEventGetFaultDetectionCounter_GetFaultDetectionCounter_Event_DTC_0xe01492: start-on-event=GetFaultDetectionCounter, operation=Event_DTC_0xe01492.GetFaultDetectionCounter
        OpEventGetFaultDetectionCounter_GetFaultDetectionCounter_EvtInfo_DTC_0xc41522: start-on-event=GetFaultDetectionCounter, operation=EvtInfo_DTC_0xc41522.GetFaultDetectionCounter
        OpEventGetFaultDetectionCounter_GetFaultDetectionCounter_Event_DTC_0xc41522: start-on-event=GetFaultDetectionCounter, operation=Event_DTC_0xc41522.GetFaultDetectionCounter
        OpEventGetFaultDetectionCounter_GetFaultDetectionCounter_EvtInfo_DTC_0xc55700: start-on-event=GetFaultDetectionCounter, operation=EvtInfo_DTC_0xc55700.GetFaultDetectionCounter
        OpEventGetFaultDetectionCounter_GetFaultDetectionCounter_Event_DTC_0xc55700: start-on-event=GetFaultDetectionCounter, operation=Event_DTC_0xc55700.GetFaultDetectionCounter
        OpEventGetFaultDetectionCounter_GetFaultDetectionCounter_EvtInfo_DTC_0xc55300: start-on-event=GetFaultDetectionCounter, operation=EvtInfo_DTC_0xc55300.GetFaultDetectionCounter
        OpEventGetFaultDetectionCounter_GetFaultDetectionCounter_Event_DTC_0xc55300: start-on-event=GetFaultDetectionCounter, operation=Event_DTC_0xc55300.GetFaultDetectionCounter
        OpEventGetFaultDetectionCounter_GetFaultDetectionCounter_EvtInfo_DTC_0x5b0062: start-on-event=GetFaultDetectionCounter, operation=EvtInfo_DTC_0x5b0062.GetFaultDetectionCounter
        OpEventGetFaultDetectionCounter_GetFaultDetectionCounter_Event_DTC_0x5b0062: start-on-event=GetFaultDetectionCounter, operation=Event_DTC_0x5b0062.GetFaultDetectionCounter
        OpEventGetFaultDetectionCounter_GetFaultDetectionCounter_EvtInfo_DTC_0x511056: start-on-event=GetFaultDetectionCounter, operation=EvtInfo_DTC_0x511056.GetFaultDetectionCounter
        OpEventGetFaultDetectionCounter_GetFaultDetectionCounter_Event_DTC_0x511056: start-on-event=GetFaultDetectionCounter, operation=Event_DTC_0x511056.GetFaultDetectionCounter
        OpEventGetFaultDetectionCounter_GetFaultDetectionCounter_EvtInfo_DTC_0xc10000: start-on-event=GetFaultDetectionCounter, operation=EvtInfo_DTC_0xc10000.GetFaultDetectionCounter
        OpEventGetFaultDetectionCounter_GetFaultDetectionCounter_Event_DTC_0xc10000: start-on-event=GetFaultDetectionCounter, operation=Event_DTC_0xc10000.GetFaultDetectionCounter
        OpEventGetFaultDetectionCounter_GetFaultDetectionCounter_EvtInfo_DTC_0xe01481: start-on-event=GetFaultDetectionCounter, operation=EvtInfo_DTC_0xe01481.GetFaultDetectionCounter
        OpEventGetFaultDetectionCounter_GetFaultDetectionCounter_Event_DTC_0xe01481: start-on-event=GetFaultDetectionCounter, operation=Event_DTC_0xe01481.GetFaultDetectionCounter
        OpEventGetFaultDetectionCounter_GetFaultDetectionCounter_EvtInfo_DTC_0xc14600: start-on-event=GetFaultDetectionCounter, operation=EvtInfo_DTC_0xc14600.GetFaultDetectionCounter
        OpEventGetFaultDetectionCounter_GetFaultDetectionCounter_Event_DTC_0xc14600: start-on-event=GetFaultDetectionCounter, operation=Event_DTC_0xc14600.GetFaultDetectionCounter
        OpEventGetFaultDetectionCounter_GetFaultDetectionCounter_EvtInfo_DTC_0xe01647: start-on-event=GetFaultDetectionCounter, operation=EvtInfo_DTC_0xe01647.GetFaultDetectionCounter
        OpEventGetFaultDetectionCounter_GetFaultDetectionCounter_Event_DTC_0xe01647: start-on-event=GetFaultDetectionCounter, operation=Event_DTC_0xe01647.GetFaultDetectionCounter
        OpEventGetFaultDetectionCounter_GetFaultDetectionCounter_EvtInfo_DTC_0xe01648: start-on-event=GetFaultDetectionCounter, operation=EvtInfo_DTC_0xe01648.GetFaultDetectionCounter
        OpEventGetFaultDetectionCounter_GetFaultDetectionCounter_Event_DTC_0xe01648: start-on-event=GetFaultDetectionCounter, operation=Event_DTC_0xe01648.GetFaultDetectionCounter
        OpEventGetFaultDetectionCounter_GetFaultDetectionCounter_EvtInfo_DTC_0xc40100: start-on-event=GetFaultDetectionCounter, operation=EvtInfo_DTC_0xc40100.GetFaultDetectionCounter
        OpEventGetFaultDetectionCounter_GetFaultDetectionCounter_Event_DTC_0xc40100: start-on-event=GetFaultDetectionCounter, operation=Event_DTC_0xc40100.GetFaultDetectionCounter
        OpEventGetFaultDetectionCounter_GetFaultDetectionCounter_EvtInfo_DTC_0xc53b00: start-on-event=GetFaultDetectionCounter, operation=EvtInfo_DTC_0xc53b00.GetFaultDetectionCounter
        OpEventGetFaultDetectionCounter_GetFaultDetectionCounter_Event_DTC_0xc53b00: start-on-event=GetFaultDetectionCounter, operation=Event_DTC_0xc53b00.GetFaultDetectionCounter
        OpEventGetFaultDetectionCounter_GetFaultDetectionCounter_EvtInfo_DTC_0xf00061: start-on-event=GetFaultDetectionCounter, operation=EvtInfo_DTC_0xf00061.GetFaultDetectionCounter
        OpEventGetFaultDetectionCounter_GetFaultDetectionCounter_Event_DTC_0xf00061: start-on-event=GetFaultDetectionCounter, operation=Event_DTC_0xf00061.GetFaultDetectionCounter
        OpEventGetFaultDetectionCounter_GetFaultDetectionCounter_EvtInfo_DTC_0x600d49: start-on-event=GetFaultDetectionCounter, operation=EvtInfo_DTC_0x600d49.GetFaultDetectionCounter
        OpEventGetFaultDetectionCounter_GetFaultDetectionCounter_Event_DTC_0x600d49: start-on-event=GetFaultDetectionCounter, operation=Event_DTC_0x600d49.GetFaultDetectionCounter
        OpEventGetFaultDetectionCounter_GetFaultDetectionCounter_EvtInfo_DTC_0xc55400: start-on-event=GetFaultDetectionCounter, operation=EvtInfo_DTC_0xc55400.GetFaultDetectionCounter
        OpEventGetFaultDetectionCounter_GetFaultDetectionCounter_Event_DTC_0xc55400: start-on-event=GetFaultDetectionCounter, operation=Event_DTC_0xc55400.GetFaultDetectionCounter
        OpEventGetFaultDetectionCounter_GetFaultDetectionCounter_EvtInfo_DTC_0xe01478: start-on-event=GetFaultDetectionCounter, operation=EvtInfo_DTC_0xe01478.GetFaultDetectionCounter
        OpEventGetFaultDetectionCounter_GetFaultDetectionCounter_Event_DTC_0xe01478: start-on-event=GetFaultDetectionCounter, operation=Event_DTC_0xe01478.GetFaultDetectionCounter
        OpEventGetFaultDetectionCounter_GetFaultDetectionCounter_EvtInfo_DTC_0x502d00: start-on-event=GetFaultDetectionCounter, operation=EvtInfo_DTC_0x502d00.GetFaultDetectionCounter
        OpEventGetFaultDetectionCounter_GetFaultDetectionCounter_Event_DTC_0x502d00: start-on-event=GetFaultDetectionCounter, operation=Event_DTC_0x502d00.GetFaultDetectionCounter
        OpEventGetFaultDetectionCounter_GetFaultDetectionCounter_EvtInfo_DTC_0xc12200: start-on-event=GetFaultDetectionCounter, operation=EvtInfo_DTC_0xc12200.GetFaultDetectionCounter
        OpEventGetFaultDetectionCounter_GetFaultDetectionCounter_Event_DTC_0xc12200: start-on-event=GetFaultDetectionCounter, operation=Event_DTC_0xc12200.GetFaultDetectionCounter
        OpEventGetFaultDetectionCounter_GetFaultDetectionCounter_EvtInfo_DTC_0xc12600: start-on-event=GetFaultDetectionCounter, operation=EvtInfo_DTC_0xc12600.GetFaultDetectionCounter
        OpEventGetFaultDetectionCounter_GetFaultDetectionCounter_Event_DTC_0xc12600: start-on-event=GetFaultDetectionCounter, operation=Event_DTC_0xc12600.GetFaultDetectionCounter
        OpEventGetFaultDetectionCounter_GetFaultDetectionCounter_EvtInfo_DTC_0xf00368: start-on-event=GetFaultDetectionCounter, operation=EvtInfo_DTC_0xf00368.GetFaultDetectionCounter
        OpEventGetFaultDetectionCounter_GetFaultDetectionCounter_Event_DTC_0xf00368: start-on-event=GetFaultDetectionCounter, operation=Event_DTC_0xf00368.GetFaultDetectionCounter
        OpEventGetFaultDetectionCounter_GetFaultDetectionCounter_EvtInfo_DTC_0x600d62: start-on-event=GetFaultDetectionCounter, operation=EvtInfo_DTC_0x600d62.GetFaultDetectionCounter
        OpEventGetFaultDetectionCounter_GetFaultDetectionCounter_Event_DTC_0x600d62: start-on-event=GetFaultDetectionCounter, operation=Event_DTC_0x600d62.GetFaultDetectionCounter
        OpEventGetFaultDetectionCounter_GetFaultDetectionCounter_EvtInfo_DTC_0xc42300: start-on-event=GetFaultDetectionCounter, operation=EvtInfo_DTC_0xc42300.GetFaultDetectionCounter
        OpEventGetFaultDetectionCounter_GetFaultDetectionCounter_Event_DTC_0xc42300: start-on-event=GetFaultDetectionCounter, operation=Event_DTC_0xc42300.GetFaultDetectionCounter
        OpEventGetFaultDetectionCounter_GetFaultDetectionCounter_EvtInfo_DTC_0xc53c00: start-on-event=GetFaultDetectionCounter, operation=EvtInfo_DTC_0xc53c00.GetFaultDetectionCounter
        OpEventGetFaultDetectionCounter_GetFaultDetectionCounter_Event_DTC_0xc53c00: start-on-event=GetFaultDetectionCounter, operation=Event_DTC_0xc53c00.GetFaultDetectionCounter
        OpEventGetFaultDetectionCounter_GetFaultDetectionCounter_EvtInfo_DTC_0xe30055: start-on-event=GetFaultDetectionCounter, operation=EvtInfo_DTC_0xe30055.GetFaultDetectionCounter
        OpEventGetFaultDetectionCounter_GetFaultDetectionCounter_Event_DTC_0xe30055: start-on-event=GetFaultDetectionCounter, operation=Event_DTC_0xe30055.GetFaultDetectionCounter
        OpEventGetFaultDetectionCounter_GetFaultDetectionCounter_EvtInfo_DTC_0x600c49: start-on-event=GetFaultDetectionCounter, operation=EvtInfo_DTC_0x600c49.GetFaultDetectionCounter
        OpEventGetFaultDetectionCounter_GetFaultDetectionCounter_Event_DTC_0x600c49: start-on-event=GetFaultDetectionCounter, operation=Event_DTC_0x600c49.GetFaultDetectionCounter
        OpEventGetFaultDetectionCounter_GetFaultDetectionCounter_EvtInfo_DTC_0xc23b00: start-on-event=GetFaultDetectionCounter, operation=EvtInfo_DTC_0xc23b00.GetFaultDetectionCounter
        OpEventGetFaultDetectionCounter_GetFaultDetectionCounter_Event_DTC_0xc23b00: start-on-event=GetFaultDetectionCounter, operation=Event_DTC_0xc23b00.GetFaultDetectionCounter
        OpEventGetFaultDetectionCounter_GetFaultDetectionCounter_EvtInfo_DTC_0xc41600: start-on-event=GetFaultDetectionCounter, operation=EvtInfo_DTC_0xc41600.GetFaultDetectionCounter
        OpEventGetFaultDetectionCounter_GetFaultDetectionCounter_Event_DTC_0xc41600: start-on-event=GetFaultDetectionCounter, operation=Event_DTC_0xc41600.GetFaultDetectionCounter
        OpEventGetFaultDetectionCounter_GetFaultDetectionCounter_EvtInfo_DTC_0x9d234b: start-on-event=GetFaultDetectionCounter, operation=EvtInfo_DTC_0x9d234b.GetFaultDetectionCounter
        OpEventGetFaultDetectionCounter_GetFaultDetectionCounter_Event_DTC_0x9d234b: start-on-event=GetFaultDetectionCounter, operation=Event_DTC_0x9d234b.GetFaultDetectionCounter
        OpEventGetFaultDetectionCounter_GetFaultDetectionCounter_EvtInfo_DTC_0xc10200: start-on-event=GetFaultDetectionCounter, operation=EvtInfo_DTC_0xc10200.GetFaultDetectionCounter
        OpEventGetFaultDetectionCounter_GetFaultDetectionCounter_Event_DTC_0xc10200: start-on-event=GetFaultDetectionCounter, operation=Event_DTC_0xc10200.GetFaultDetectionCounter
        OpEventGetFaultDetectionCounter_GetFaultDetectionCounter_EvtInfo_DTC_0xc12100: start-on-event=GetFaultDetectionCounter, operation=EvtInfo_DTC_0xc12100.GetFaultDetectionCounter
        OpEventGetFaultDetectionCounter_GetFaultDetectionCounter_Event_DTC_0xc12100: start-on-event=GetFaultDetectionCounter, operation=Event_DTC_0xc12100.GetFaultDetectionCounter
        OpEventGetFaultDetectionCounter_GetFaultDetectionCounter_EvtInfo_DTC_0xc42800: start-on-event=GetFaultDetectionCounter, operation=EvtInfo_DTC_0xc42800.GetFaultDetectionCounter
        OpEventGetFaultDetectionCounter_GetFaultDetectionCounter_Event_DTC_0xc42800: start-on-event=GetFaultDetectionCounter, operation=Event_DTC_0xc42800.GetFaultDetectionCounter
        OpEventGetFaultDetectionCounter_GetFaultDetectionCounter_EvtInfo_DTC_0xc14000: start-on-event=GetFaultDetectionCounter, operation=EvtInfo_DTC_0xc14000.GetFaultDetectionCounter
        OpEventGetFaultDetectionCounter_GetFaultDetectionCounter_Event_DTC_0xc14000: start-on-event=GetFaultDetectionCounter, operation=Event_DTC_0xc14000.GetFaultDetectionCounter
        OpEventGetFaultDetectionCounter_GetFaultDetectionCounter_EvtInfo_DTC_0xc45a00: start-on-event=GetFaultDetectionCounter, operation=EvtInfo_DTC_0xc45a00.GetFaultDetectionCounter
        OpEventGetFaultDetectionCounter_GetFaultDetectionCounter_Event_DTC_0xc45a00: start-on-event=GetFaultDetectionCounter, operation=Event_DTC_0xc45a00.GetFaultDetectionCounter
        OpEventGetFaultDetectionCounter_GetFaultDetectionCounter_EvtInfo_DTC_0xc25300: start-on-event=GetFaultDetectionCounter, operation=EvtInfo_DTC_0xc25300.GetFaultDetectionCounter
        OpEventGetFaultDetectionCounter_GetFaultDetectionCounter_Event_DTC_0xc25300: start-on-event=GetFaultDetectionCounter, operation=Event_DTC_0xc25300.GetFaultDetectionCounter
        OpEventGetFaultDetectionCounter_GetFaultDetectionCounter_EvtInfo_DTC_0x600c62: start-on-event=GetFaultDetectionCounter, operation=EvtInfo_DTC_0x600c62.GetFaultDetectionCounter
        OpEventGetFaultDetectionCounter_GetFaultDetectionCounter_Event_DTC_0x600c62: start-on-event=GetFaultDetectionCounter, operation=Event_DTC_0x600c62.GetFaultDetectionCounter
        OpEventGetFaultDetectionCounter_GetFaultDetectionCounter_EvtInfo_DTC_0xc42200: start-on-event=GetFaultDetectionCounter, operation=EvtInfo_DTC_0xc42200.GetFaultDetectionCounter
        OpEventGetFaultDetectionCounter_GetFaultDetectionCounter_Event_DTC_0xc42200: start-on-event=GetFaultDetectionCounter, operation=Event_DTC_0xc42200.GetFaultDetectionCounter
        OpEventGetFaultDetectionCounter_GetFaultDetectionCounter_EvtInfo_DTC_0xc40300: start-on-event=GetFaultDetectionCounter, operation=EvtInfo_DTC_0xc40300.GetFaultDetectionCounter
        OpEventGetFaultDetectionCounter_GetFaultDetectionCounter_Event_DTC_0xc40300: start-on-event=GetFaultDetectionCounter, operation=Event_DTC_0xc40300.GetFaultDetectionCounter
        OpEventGetFaultDetectionCounter_GetFaultDetectionCounter_EvtInfo_DTC_0x600b49: start-on-event=GetFaultDetectionCounter, operation=EvtInfo_DTC_0x600b49.GetFaultDetectionCounter
        OpEventGetFaultDetectionCounter_GetFaultDetectionCounter_Event_DTC_0x600b49: start-on-event=GetFaultDetectionCounter, operation=Event_DTC_0x600b49.GetFaultDetectionCounter
        OpEventGetFaultDetectionCounter_GetFaultDetectionCounter_EvtInfo_DTC_0xc15900: start-on-event=GetFaultDetectionCounter, operation=EvtInfo_DTC_0xc15900.GetFaultDetectionCounter
        OpEventGetFaultDetectionCounter_GetFaultDetectionCounter_Event_DTC_0xc15900: start-on-event=GetFaultDetectionCounter, operation=Event_DTC_0xc15900.GetFaultDetectionCounter
        OpEventGetFaultDetectionCounter_GetFaultDetectionCounter_EvtInfo_DTC_0xc23a00: start-on-event=GetFaultDetectionCounter, operation=EvtInfo_DTC_0xc23a00.GetFaultDetectionCounter
        OpEventGetFaultDetectionCounter_GetFaultDetectionCounter_Event_DTC_0xc23a00: start-on-event=GetFaultDetectionCounter, operation=Event_DTC_0xc23a00.GetFaultDetectionCounter
        OpEventGetFaultDetectionCounter_GetFaultDetectionCounter_EvtInfo_DTC_0xc15500: start-on-event=GetFaultDetectionCounter, operation=EvtInfo_DTC_0xc15500.GetFaultDetectionCounter
        OpEventGetFaultDetectionCounter_GetFaultDetectionCounter_Event_DTC_0xc15500: start-on-event=GetFaultDetectionCounter, operation=Event_DTC_0xc15500.GetFaultDetectionCounter
        OpEventGetFaultDetectionCounter_GetFaultDetectionCounter_EvtInfo_DTC_0xc41500: start-on-event=GetFaultDetectionCounter, operation=EvtInfo_DTC_0xc41500.GetFaultDetectionCounter
        OpEventGetFaultDetectionCounter_GetFaultDetectionCounter_Event_DTC_0xc41500: start-on-event=GetFaultDetectionCounter, operation=Event_DTC_0xc41500.GetFaultDetectionCounter
        OpEventGetFaultDetectionCounter_GetFaultDetectionCounter_EvtInfo_DTC_0x5b0049: start-on-event=GetFaultDetectionCounter, operation=EvtInfo_DTC_0x5b0049.GetFaultDetectionCounter
        OpEventGetFaultDetectionCounter_GetFaultDetectionCounter_Event_DTC_0x5b0049: start-on-event=GetFaultDetectionCounter, operation=Event_DTC_0x5b0049.GetFaultDetectionCounter
        OpEventGetFaultDetectionCounter_GetFaultDetectionCounter_EvtInfo_DTC_0xf00317: start-on-event=GetFaultDetectionCounter, operation=EvtInfo_DTC_0xf00317.GetFaultDetectionCounter
        OpEventGetFaultDetectionCounter_GetFaultDetectionCounter_Event_DTC_0xf00317: start-on-event=GetFaultDetectionCounter, operation=Event_DTC_0xf00317.GetFaultDetectionCounter
        OpEventGetFaultDetectionCounter_GetFaultDetectionCounter_EvtInfo_DTC_0xf00316: start-on-event=GetFaultDetectionCounter, operation=EvtInfo_DTC_0xf00316.GetFaultDetectionCounter
        OpEventGetFaultDetectionCounter_GetFaultDetectionCounter_Event_DTC_0xf00316: start-on-event=GetFaultDetectionCounter, operation=Event_DTC_0xf00316.GetFaultDetectionCounter
        OpEventGetEventFreezeFrameData_GetEventFreezeFrameData_EvtInfo_DTC_0x600b62: start-on-event=GetEventFreezeFrameData, operation=EvtInfo_DTC_0x600b62.GetEventFreezeFrameData
        OpEventGetEventFreezeFrameData_GetEventFreezeFrameData_Event_DTC_0x600b62: start-on-event=GetEventFreezeFrameData, operation=Event_DTC_0x600b62.GetEventFreezeFrameData
        OpEventGetEventFreezeFrameData_GetEventFreezeFrameData_EvtInfo_DTC_0xc25600: start-on-event=GetEventFreezeFrameData, operation=EvtInfo_DTC_0xc25600.GetEventFreezeFrameData
        OpEventGetEventFreezeFrameData_GetEventFreezeFrameData_Event_DTC_0xc25600: start-on-event=GetEventFreezeFrameData, operation=Event_DTC_0xc25600.GetEventFreezeFrameData
        OpEventGetEventFreezeFrameData_GetEventFreezeFrameData_EvtInfo_DTC_0xf00049: start-on-event=GetEventFreezeFrameData, operation=EvtInfo_DTC_0xf00049.GetEventFreezeFrameData
        OpEventGetEventFreezeFrameData_GetEventFreezeFrameData_Event_DTC_0xf00049: start-on-event=GetEventFreezeFrameData, operation=Event_DTC_0xf00049.GetEventFreezeFrameData
        OpEventGetEventFreezeFrameData_GetEventFreezeFrameData_EvtInfo_DTC_0xe10000: start-on-event=GetEventFreezeFrameData, operation=EvtInfo_DTC_0xe10000.GetEventFreezeFrameData
        OpEventGetEventFreezeFrameData_GetEventFreezeFrameData_Event_DTC_0xe10000: start-on-event=GetEventFreezeFrameData, operation=Event_DTC_0xe10000.GetEventFreezeFrameData
        OpEventGetEventFreezeFrameData_GetEventFreezeFrameData_EvtInfo_DTC_0xf00168: start-on-event=GetEventFreezeFrameData, operation=EvtInfo_DTC_0xf00168.GetEventFreezeFrameData
        OpEventGetEventFreezeFrameData_GetEventFreezeFrameData_Event_DTC_0xf00168: start-on-event=GetEventFreezeFrameData, operation=Event_DTC_0xf00168.GetEventFreezeFrameData
        OpEventGetEventFreezeFrameData_GetEventFreezeFrameData_EvtInfo_DTC_0xf00042: start-on-event=GetEventFreezeFrameData, operation=EvtInfo_DTC_0xf00042.GetEventFreezeFrameData
        OpEventGetEventFreezeFrameData_GetEventFreezeFrameData_Event_DTC_0xf00042: start-on-event=GetEventFreezeFrameData, operation=Event_DTC_0xf00042.GetEventFreezeFrameData
        OpEventGetEventFreezeFrameData_GetEventFreezeFrameData_EvtInfo_DTC_0xc25200: start-on-event=GetEventFreezeFrameData, operation=EvtInfo_DTC_0xc25200.GetEventFreezeFrameData
